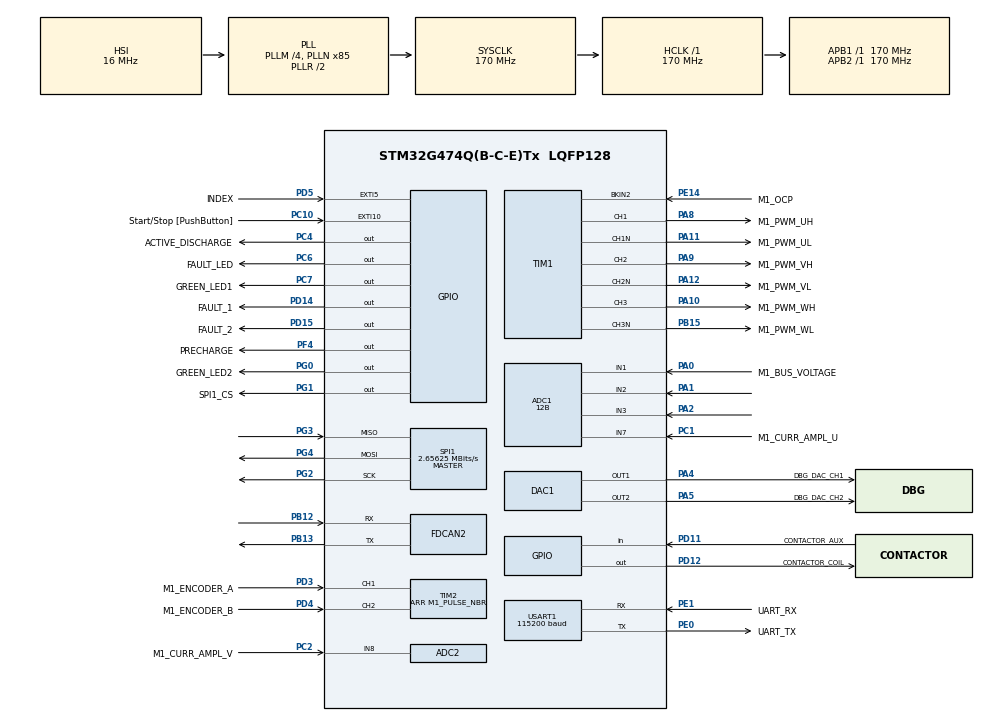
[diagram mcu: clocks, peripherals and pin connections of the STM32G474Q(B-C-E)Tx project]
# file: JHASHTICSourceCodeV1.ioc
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ADC1.Channel-1\#ChannelRegularConversion=ADC_CHANNEL_1
ADC1.Channel-2\#ChannelRegularConversion=ADC_CHANNEL_2
ADC1.Channel-3\#ChannelRegularConversion=ADC_CHANNEL_3
ADC1.ClockPrescaler=ADC_CLOCK_ASYNC_DIV4
ADC1.ContinuousConvMode=DISABLE
ADC1.DMAContinuousRequests=DISABLE
ADC1.DataAlign=ADC_DATAALIGN_LEFT
ADC1.DiscontinuousConvMode=DISABLE
ADC1.EOCSelection=ADC_EOC_SINGLE_CONV
ADC1.EnableAnalogWatchDog1=false
ADC1.EnableAnalogWatchDog2=false
ADC1.EnableAnalogWatchDog3=false
ADC1.EnableInjectedConversion=ENABLE
ADC1.EnableRegularConversion=ENABLE
ADC1.ExternalTrigConv=ADC_SOFTWARE_START
ADC1.ExternalTrigConvEdge=ADC_EXTERNALTRIGCONVEDGE_NONE
ADC1.ExternalTrigInjecConv=ADC_EXTERNALTRIGINJEC_T1_TRGO
ADC1.ExternalTrigInjecConvEdge=ADC_EXTERNALTRIGINJECCONV_EDGE_RISING
ADC1.InjNumberOfConversion=1
ADC1.InjectedChannel-1\#ChannelInjectedConversion=ADC_CHANNEL_7
ADC1.InjectedConvMode=None
ADC1.InjectedOffset-1\#ChannelInjectedConversion=0
ADC1.InjectedOffsetNumber-1\#ChannelInjectedConversion=ADC_OFFSET_NONE
ADC1.InjectedRank-1\#ChannelInjectedConversion=1
ADC1.InjectedSamplingTime-1\#ChannelInjectedConversion=ADC_SAMPLETIME_6CYCLES_5
ADC1.LowPowerAutoWait=DISABLE
ADC1.NbrOfConversion=3
ADC1.NbrOfConversionFlag=1
ADC1.Offset-1\#ChannelRegularConversion=0
ADC1.OffsetNumber-1\#ChannelRegularConversion=ADC_OFFSET_NONE
ADC1.OffsetNumber-2\#ChannelRegularConversion=ADC_OFFSET_NONE
ADC1.OffsetNumber-3\#ChannelRegularConversion=ADC_OFFSET_NONE
ADC1.Overrun=ADC_OVR_DATA_PRESERVED
ADC1.Rank-1\#ChannelRegularConversion=1
ADC1.Rank-2\#ChannelRegularConversion=2
ADC1.Rank-3\#ChannelRegularConversion=3
ADC1.Resolution=ADC_RESOLUTION_12B
ADC1.SamplingTime-1\#ChannelRegularConversion=ADC_SAMPLETIME_47CYCLES_5
ADC1.SamplingTime-2\#ChannelRegularConversion=ADC_SAMPLETIME_2CYCLES_5
ADC1.SamplingTime-3\#ChannelRegularConversion=ADC_SAMPLETIME_2CYCLES_5
ADC1.ScanConvMode=ADC_SCAN_ENABLE
ADC1.master=1
ADC2.ClockPrescaler=ADC_CLOCK_ASYNC_DIV4
ADC2.ContinuousConvMode=DISABLE
ADC2.DMAContinuousRequests=DISABLE
ADC2.DataAlign=ADC_DATAALIGN_LEFT
ADC2.DiscontinuousConvMode=DISABLE
ADC2.EOCSelection=ADC_EOC_SINGLE_CONV
ADC2.EnableAnalogWatchDog1=false
ADC2.EnableAnalogWatchDog2=false
ADC2.EnableAnalogWatchDog3=false
ADC2.EnableInjectedConversion=ENABLE
ADC2.EnableRegularConversion=DISABLE
ADC2.ExternalTrigInjecConv=ADC_EXTERNALTRIGINJEC_T1_TRGO
ADC2.ExternalTrigInjecConvEdge=ADC_EXTERNALTRIGINJECCONV_EDGE_RISING
ADC2.InjNumberOfConversion=1
ADC2.InjectedChannel-1\#ChannelInjectedConversion=ADC_CHANNEL_8
ADC2.InjectedConvMode=None
ADC2.InjectedOffset-1\#ChannelInjectedConversion=0
ADC2.InjectedOffsetNumber-1\#ChannelInjectedConversion=ADC_OFFSET_NONE
ADC2.InjectedRank-1\#ChannelInjectedConversion=1
ADC2.InjectedSamplingTime-1\#ChannelInjectedConversion=ADC_SAMPLETIME_6CYCLES_5
ADC2.LowPowerAutoWait=DISABLE
ADC2.Overrun=ADC_OVR_DATA_PRESERVED
ADC2.Resolution=ADC_RESOLUTION_12B
ADC2.ScanConvMode=ADC_SCAN_DISABLE
DAC1.DAC_Channel-DAC_OUT2=DAC_CHANNEL_2
DAC1.DAC_OutputBuffer=DAC_OUTPUTBUFFER_DISABLE
DAC1.DAC_OutputBuffer2=DAC_OUTPUTBUFFER_DISABLE
DAC1.DAC_Trigger_OUT1=DAC_TRIGGER_SOFTWARE
ExtraMW=MotorControl
ExtraMW.MotorControl.Config=MotorControl
ExtraMW.MotorControl.Mode=MotorControl
ExtraMW.MotorControl.Root=MCSDK_v5.4.7/MotorControl
ExtraMW.MotorControl.Template=templates
FDCAN2.AutoRetransmission=DISABLE
FDCAN2.DataPrescaler=1
FDCAN2.DataSyncJumpWidth=1
FDCAN2.DataTimeSeg1=1
FDCAN2.DataTimeSeg2=1
FDCAN2.FrameFormat=FDCAN_FRAME_CLASSIC
FDCAN2.NominalPrescaler=17
FDCAN2.NominalSyncJumpWidth=1
FDCAN2.NominalTimeSeg1=2
FDCAN2.NominalTimeSeg2=2
FDCAN2.TransmitPause=ENABLE
Mcu.Family=STM32G4
Mcu.Name=STM32G474Q(B-C-E)Tx
Mcu.Package=LQFP128
MotorControl.ADC_1_PERIPH=ADC1
MotorControl.ADC_2_PERIPH=ADC2
MotorControl.ADC_AHBPERIPH=RCC_AHBPeriph_ADC12
MotorControl.ADC_CLOCK_WB_DIV=4
MotorControl.ADC_CLOCK_WB_FREQ=42.5
MotorControl.ADC_PERIPH=ADC1
MotorControl.ADC_REFERENCE_VOLTAGE=3.30
MotorControl.ALIGNMENT_ANGLE_DEG=0
MotorControl.ALIGNMENT_DURATION=700
MotorControl.AMPLIFICATION_GAIN=0.009
MotorControl.ANGC={0,0,0,0,0,0,0,0}
MotorControl.BEMF_CONSISTENCY_GAIN=64
MotorControl.BEMF_CONSISTENCY_TOL=64
MotorControl.BKIN1_FILTER=0
MotorControl.BKIN2_FILTER=0
MotorControl.BKIN2_MODE=EXT_MODE
MotorControl.BKIN_MODE=NONE
MotorControl.BOARD=CUSTOM
MotorControl.BRKIN2_GPIO_AF=GPIO_AF_2
MotorControl.BRKIN_GPIO_AF=GPIO_AF_2
MotorControl.BUS_VOLTAGE_READING=true
MotorControl.CCMRAM_ENABLED=false
MotorControl.CLOCK_FREQUENCY=CPU_CLK_170_MHZ
MotorControl.CLOCK_SOURCE=INTERNAL
MotorControl.CONSTANT1_D=44442
MotorControl.CONSTANT1_Q=70509
MotorControl.CONSTANT2_QD=4316
MotorControl.CORD_BEMF_CONSISTENCY_GAIN=64
MotorControl.CORD_BEMF_CONSISTENCY_TOL=64
MotorControl.CORD_F1=16384
MotorControl.CORD_F2=8192
MotorControl.CORD_FIFO_DEPTH_01HZ=64
MotorControl.CORD_FIFO_DEPTH_DPP=64
MotorControl.CORD_GAIN1=-24465
MotorControl.CORD_GAIN2=30068
MotorControl.CORD_MAX_ACCEL_DPPP=193
MotorControl.CORD_MEAS_ERRORS_BEFORE_FAULTS=255
MotorControl.CORD_VARIANCE_THRESHOLD=4
MotorControl.CPU_CLK_170_MHZ=true
MotorControl.CTRBDID=0
MotorControl.CUBE_MX_VER=5.3.0
MotorControl.CURRENT_READING_TOPOLOGY=ICS_SENSORS
MotorControl.CURR_SAMPLING_TIME=6
MotorControl.DAC_EMULATED=false
MotorControl.DAC_FUNCTIONALITY=true
MotorControl.DAC_TIMER_CH1_GPIO_PIN=LL_GPIO_PIN_4
MotorControl.DAC_TIMER_CH1_GPIO_PORT=GPIOA
MotorControl.DAC_TIMER_CH2_GPIO_PIN=LL_GPIO_PIN_5
MotorControl.DAC_TIMER_CH2_GPIO_PORT=GPIOA
MotorControl.DAC_TIMER_SELECTION=TIM3
MotorControl.DC_CURRENT_RS_MEAS=30.00
MotorControl.DEBUG_DAC_CH1=true
MotorControl.DEBUG_DAC_CH2=true
MotorControl.DEFAULT_CONTROL_MODE=STC_SPEED_MODE
MotorControl.DEFAULT_DAC_CHANNEL_1=MC_PROTOCOL_REG_I_A
MotorControl.DEFAULT_DAC_CHANNEL_2=MC_PROTOCOL_REG_I_B
MotorControl.DEFAULT_DAC_MOTOR=0
MotorControl.DEFAULT_FLUX_COMPONENT=0
MotorControl.DEFAULT_TARGET_SPEED_RPM=0
MotorControl.DEFAULT_TORQUE_COMPONENT=0
MotorControl.DISSIPATIVE_BRAKE_POLARITY=DOUT_ACTIVE_HIGH
MotorControl.DRIVES_NUMBER_SELECTION=SINGLEDRIVE
MotorControl.EMERGENCY2_STOP_GPIO_PIN=LL_GPIO_PIN_14
MotorControl.EMERGENCY2_STOP_GPIO_PORT=GPIOE
MotorControl.EMERGENCY_STOP_GPIO_PIN=LL_GPIO_PIN_14
MotorControl.EMERGENCY_STOP_GPIO_PORT=GPIOE
MotorControl.ENABLE_SL_ALGO_FROM_PHASE=3
MotorControl.ENCODER=true
MotorControl.ENCODER_AVAILABLE=true
MotorControl.ENCODER_PPR=512
MotorControl.ENC_AVERAGING_FIFO_DEPTH=16
MotorControl.ENC_A_GPIO_PIN=LL_GPIO_PIN_3
MotorControl.ENC_A_GPIO_PORT=GPIOD
MotorControl.ENC_B_GPIO_PIN=LL_GPIO_PIN_4
MotorControl.ENC_B_GPIO_PORT=GPIOD
MotorControl.ENC_ICx_FILTER=128
MotorControl.ENC_INVERT_SPEED=false
MotorControl.ENC_MEAS_ERRORS_BEFORE_FAULTS=255
MotorControl.ENC_TIMER_REMAPPING=NO_REMAP_TIM2
MotorControl.ENC_TIMER_SELECTION=ENC_TIM2
MotorControl.ENC_USE_CH3=false
MotorControl.EXT_CLOCK_FREQUENCY=INT_RC_OSC
MotorControl.F1=16384
MotorControl.F2=8192
MotorControl.FEEDBACK_NET_FILTERING=false
MotorControl.FEED_FORWARD_CURRENT_REG_ENABLING=false
MotorControl.FINAL_I_ALIGNMENT=348
MotorControl.FLUX_WEAKENING_ENABLING=false
MotorControl.FW_KIDIV=32768
MotorControl.FW_KI_GAIN=5000
MotorControl.FW_KPDIV=32768
MotorControl.FW_KP_GAIN=3000
MotorControl.FW_VOLTAGE_REF=985
MotorControl.GAIN1=-24465
MotorControl.GAIN2=30068
MotorControl.H1_GPIO_PIN=LL_GPIO_PIN_0
MotorControl.H1_GPIO_PORT=GPIOA
MotorControl.H2_GPIO_PIN=LL_GPIO_PIN_3
MotorControl.H2_GPIO_PORT=GPIOB
MotorControl.H3_GPIO_PIN=LL_GPIO_PIN_10
MotorControl.H3_GPIO_PORT=GPIOB
MotorControl.HALL_AVERAGING_FIFO_DEPTH=6
MotorControl.HALL_ICx_FILTER=221
MotorControl.HALL_MEAS_ERRORS_BEFORE_FAULTS=255
MotorControl.HALL_MTPA=false
MotorControl.HALL_PHASE_SHIFT=300
MotorControl.HALL_SENSORS_AVAILABLE=false
MotorControl.HALL_SENSORS_PLACEMENT=DEGREES_120
MotorControl.HALL_TIMER_REMAPPING=NO_REMAP_TIM2
MotorControl.HALL_TIMER_SELECTION=HALL_TIM2
MotorControl.HFI_AMPLITUDE=25
MotorControl.HFI_DC_0_COEFF=0.00146
MotorControl.HFI_DC_1_COEFF=0.002921
MotorControl.HFI_DC_2_COEFF=0.00146
MotorControl.HFI_DC_3_COEFF=1.889033
MotorControl.HFI_DC_4_COEFF=-0.894874
MotorControl.HFI_DEBUG_MODE=false
MotorControl.HFI_FREQUENCY=400
MotorControl.HFI_HIFRAMPLSCAN=25
MotorControl.HFI_HP_ID_0_COEFF=0.883002
MotorControl.HFI_HP_ID_1_COEFF=-1.766004
MotorControl.HFI_HP_ID_2_COEFF=0.883002
MotorControl.HFI_HP_ID_3_COEFF=1.752268
MotorControl.HFI_HP_ID_4_COEFF=-0.779739
MotorControl.HFI_IDH_DELAY=32400
MotorControl.HFI_LOCKFREQ=66
MotorControl.HFI_LP_ID_0_COEFF=0.021558
MotorControl.HFI_LP_ID_1_COEFF=0.043117
MotorControl.HFI_LP_ID_2_COEFF=0.021558
MotorControl.HFI_LP_ID_3_COEFF=1.543836
MotorControl.HFI_LP_ID_4_COEFF=-0.63007
MotorControl.HFI_MAXANGLEDIFF=3640
MotorControl.HFI_MINIMUM_SPEED_RPM=402
MotorControl.HFI_NOTCH_IQD_0_COEFF=0.941467
MotorControl.HFI_NOTCH_IQD_1_COEFF=-1.823778
MotorControl.HFI_NOTCH_IQD_2_COEFF=0.941467
MotorControl.HFI_NOTCH_IQD_3_COEFF=1.823778
MotorControl.HFI_NOTCH_IQD_4_COEFF=-0.882933
MotorControl.HFI_NSDETPOINTSSKIP=10
MotorControl.HFI_NSMAXDETPOINTS=20
MotorControl.HFI_NS_MIN_SAT_DIFF=0
MotorControl.HFI_PID_KIDIV=32768
MotorControl.HFI_PID_KI_DEFAULT=400
MotorControl.HFI_PID_KPDIV=16384
MotorControl.HFI_PID_KP_DEFAULT=800
MotorControl.HFI_PLL_KI_DEFAULT=0.00400
MotorControl.HFI_PLL_KP_DEFAULT=0.00060
MotorControl.HFI_RESTARTTIMESEC=0.1
MotorControl.HFI_RESTART_RPM_TH=(((HFI_STO_RPM_TH)+(STO_HFI_RPM_TH))/2)
MotorControl.HFI_REVERT_DIRECTION=true
MotorControl.HFI_SCANROTATIONSNO=3
MotorControl.HFI_SPD_BUFFER_DEPTH_01HZ=64
MotorControl.HFI_STEPANGLE=3640
MotorControl.HFI_STO_RPM_TH=OBS_MINIMUM_SPEED_RPM
MotorControl.HFI_WAITAFTERNS2=4
MotorControl.HFI_WAITBEFORESN=6
MotorControl.HFI_WAITSYNCH=20
MotorControl.HFI_WAITTRACK=20
MotorControl.HIGH_SIDE_BRAKE_STATE=false
MotorControl.HIGH_SIDE_IDLE_STATE=false
MotorControl.HW_COMPLEMENTED_LOW_SIDE=false
MotorControl.HW_DEAD_TIME_NS=100
MotorControl.HW_OV_CURRENT_PROT_BYPASS=false
MotorControl.ICS_SENSORS=true
MotorControl.ID_DEMAG=-5361
MotorControl.INRUSH_CURRLIMIT_AT_POWER_ON=true
MotorControl.INRUSH_CURRLIMIT_CHANGE_AFTER_MS=1000
MotorControl.INRUSH_CURRLIMIT_ENABLING=false
MotorControl.INRUSH_CURRLIMIT_GPIO_PIN=LL_GPIO_PIN_4
MotorControl.INRUSH_CURRLIMIT_GPIO_PORT=GPIOE
MotorControl.INRUSH_CURR_LIMITER_POLARITY=DOUT_ACTIVE_HIGH
MotorControl.INTERNAL_OVERCURRENTPROTECTION=false
MotorControl.INTERNAL_OVERVOLTAGEPROTECTION=false
MotorControl.INT_RC_OSC=true
MotorControl.IPs=CORDIC,NVIC,RCC,SYS,MotorControl,TIM1,ADC1,ADC2,TIM2,DAC1,USART1
MotorControl.IQMAX=5361
MotorControl.LCD_JOYSTICK_FUNCTIONALITY=false
MotorControl.LCD_MODE=LCD_FULL
MotorControl.LDLQ_RATIO=0.630
MotorControl.LOW_SIDE_BRAKE_STATE=false
MotorControl.LOW_SIDE_IDLE_STATE=false
MotorControl.LOW_SIDE_SIGNALS_ENABLING=LS_PWM_TIMER
MotorControl.LS=0.000330
MotorControl.MAX_APPLICATION_SPEED=5000
MotorControl.MAX_MODULATION_100_PER_CENT=true
MotorControl.MAX_MODULATION_INDEX=MAX_MODULATION_100_PER_CENT
MotorControl.MCU=STM32G474QE
MotorControl.MCU_TYPE=STM32G474QE
MotorControl.MC_WORKBENCH_VERSION=5.4.7.21279
MotorControl.MEAS_ERRORS_BEFORE_FAULTS=255
MotorControl.MIN_APPLICATION_SPEED=0
MotorControl.MOTOR_MAX_SPEED_RPM=5000
MotorControl.MOTOR_TYPE=PMSM
MotorControl.MOTOR_VOLTAGE_CONSTANT=19.0
MotorControl.MTPA_ENABLING=false
MotorControl.NB_CONSECUTIVE_TESTS=2
MotorControl.NOMINAL_BUS_VOLTAGE_V=60
MotorControl.NOMINAL_CURRENT=5361
MotorControl.OBS_MEAS_ERRORS_BEFORE_FAULTS=255
MotorControl.OBS_MINIMUM_SPEED_RPM=580
MotorControl.OCPA_INVERTINGINPUT=COMPX_InvertingInput_VREF
MotorControl.OCPA_INVERTINGINPUT_GPIO_PIN=LL_GPIO_PIN_4
MotorControl.OCPA_INVERTINGINPUT_GPIO_PORT=GPIOA
MotorControl.OCPA_INVERTINGINPUT_MODE=INT_MODE
MotorControl.OCPA_NONINVERTINGINPUT=COMP1_NonInvertingInput_PA1
MotorControl.OCPA_NONINVERTINGINPUT_GPIO_PIN=LL_GPIO_PIN_1
MotorControl.OCPA_NONINVERTINGINPUT_GPIO_PORT=GPIOA
MotorControl.OCPA_OUTPUT=COMP_Output_TIM1BKIN2
MotorControl.OCPA_OUTPUTPOL=COMP_OutputPol_NonInverted
MotorControl.OCPA_OUTPUT_GPIO_AF=GPIO_AF_2
MotorControl.OCPA_OUTPUT_GPIO_PIN=LL_GPIO_PIN_0
MotorControl.OCPA_OUTPUT_GPIO_PORT=GPIOA
MotorControl.OCPA_OUTPUT_MODE=INT_MODE
MotorControl.OCPA_SELECTION=COMP1
MotorControl.OCPB_INVERTINGINPUT=COMPX_InvertingInput_VREF
MotorControl.OCPB_INVERTINGINPUT_GPIO_PIN=LL_GPIO_PIN_4
MotorControl.OCPB_INVERTINGINPUT_GPIO_PORT=GPIOA
MotorControl.OCPB_INVERTINGINPUT_MODE=INT_MODE
MotorControl.OCPB_NONINVERTINGINPUT=COMP2_NonInvertingInput_PA7
MotorControl.OCPB_NONINVERTINGINPUT_GPIO_PIN=LL_GPIO_PIN_7
MotorControl.OCPB_NONINVERTINGINPUT_GPIO_PORT=GPIOA
MotorControl.OCPB_OUTPUT=COMP_Output_TIM1BKIN2
MotorControl.OCPB_OUTPUTPOL=COMP_OutputPol_NonInverted
MotorControl.OCPB_OUTPUT_GPIO_AF=GPIO_AF_2
MotorControl.OCPB_OUTPUT_GPIO_PIN=LL_GPIO_PIN_2
MotorControl.OCPB_OUTPUT_GPIO_PORT=GPIOA
MotorControl.OCPB_OUTPUT_MODE=INT_MODE
MotorControl.OCPB_SELECTION=COMP2
MotorControl.OCPC_INVERTINGINPUT=COMPX_InvertingInput_VREF
MotorControl.OCPC_INVERTINGINPUT_GPIO_PIN=LL_GPIO_PIN_4
MotorControl.OCPC_INVERTINGINPUT_GPIO_PORT=GPIOA
MotorControl.OCPC_INVERTINGINPUT_MODE=INT_MODE
MotorControl.OCPC_NONINVERTINGINPUT=COMP3_NonInvertingInput_PD14
MotorControl.OCPC_NONINVERTINGINPUT_GPIO_PIN=LL_GPIO_PIN_14
MotorControl.OCPC_NONINVERTINGINPUT_GPIO_PORT=GPIOD
MotorControl.OCPC_OUTPUT=COMP_Output_TIM1BKIN2
MotorControl.OCPC_OUTPUTPOL=COMP_OutputPol_NonInverted
MotorControl.OCPC_OUTPUT_GPIO_AF=GPIO_AF_2
MotorControl.OCPC_OUTPUT_GPIO_PIN=LL_GPIO_PIN_8
MotorControl.OCPC_OUTPUT_GPIO_PORT=GPIOC
MotorControl.OCPC_OUTPUT_MODE=INT_MODE
MotorControl.OCPC_SELECTION=COMP3
MotorControl.OCPREF=23830
MotorControl.OCP_COMP_THRESHOLD=1.65
MotorControl.OCP_FILTER=COMP_Mode_HighSpeed
MotorControl.OCP_INVERTINGINPUT=COMPX_InvertingInput_VREF
MotorControl.OCP_INVERTINGINPUT_GPIO_PIN=LL_GPIO_PIN_4
MotorControl.OCP_INVERTINGINPUT_GPIO_PORT=GPIOA
MotorControl.OCP_INVERTINGINPUT_MODE=INT_MODE
MotorControl.OCP_NONINVERTINGINPUT=COMP2_NonInvertingInput_PA7
MotorControl.OCP_NONINVERTINGINPUT_GPIO_PIN=LL_GPIO_PIN_7
MotorControl.OCP_NONINVERTINGINPUT_GPIO_PORT=GPIOA
MotorControl.OCP_OUTPUT=COMP_Output_TIM1BKIN2
MotorControl.OCP_OUTPUTPOL=COMP_OutputPol_NonInverted
MotorControl.OCP_OUTPUT_GPIO_AF=GPIO_AF_2
MotorControl.OCP_OUTPUT_GPIO_PIN=LL_GPIO_PIN_2
MotorControl.OCP_OUTPUT_GPIO_PORT=GPIOA
MotorControl.OCP_OUTPUT_MODE=INT_MODE
MotorControl.OCP_SELECTION=COMP2
MotorControl.OFST={0,0,0,0,0,0,0,0}
MotorControl.ON_OVER_VOLTAGE=TURN_OFF_PWM
MotorControl.OPAMP1_INVERTINGINPUT=OPAMP1_InvertingInput_PGA
MotorControl.OPAMP1_INVERTINGINPUT_GPIO_PIN=LL_GPIO_PIN_3
MotorControl.OPAMP1_INVERTINGINPUT_GPIO_PORT=GPIOA
MotorControl.OPAMP1_INVERTINGINPUT_MODE=INT_MODE
MotorControl.OPAMP1_NONINVERTINGINPUT_PHA=OPAMP1_NonInvertingInput_PA1
MotorControl.OPAMP1_NONINVERTINGINPUT_PHA_GPIO_PIN=LL_GPIO_PIN_1
MotorControl.OPAMP1_NONINVERTINGINPUT_PHA_GPIO_PORT=GPIOA
MotorControl.OPAMP1_NONINVERTINGINPUT_PHB=OPAMP1_NonInvertingInput_PA7
MotorControl.OPAMP1_NONINVERTINGINPUT_PHB_GPIO_PIN=LL_GPIO_PIN_7
MotorControl.OPAMP1_NONINVERTINGINPUT_PHB_GPIO_PORT=GPIOA
MotorControl.OPAMP1_OUT_GPIO_PIN=LL_GPIO_PIN_2
MotorControl.OPAMP1_OUT_GPIO_PORT=GPIOA
MotorControl.OPAMP1_SELECTION=OPAMP1
MotorControl.OPAMP2_INVERTINGINPUT=OPAMP2_InvertingInput_PGA
MotorControl.OPAMP2_INVERTINGINPUT_GPIO_PIN=LL_GPIO_PIN_5
MotorControl.OPAMP2_INVERTINGINPUT_GPIO_PORT=GPIOC
MotorControl.OPAMP2_INVERTINGINPUT_MODE=INT_MODE
MotorControl.OPAMP2_NONINVERTINGINPUT_PHA=OPAMP2_NonInvertingInput_PB14
MotorControl.OPAMP2_NONINVERTINGINPUT_PHA_GPIO_PIN=LL_GPIO_PIN_14
MotorControl.OPAMP2_NONINVERTINGINPUT_PHA_GPIO_PORT=GPIOB
MotorControl.OPAMP2_NONINVERTINGINPUT_PHB=OPAMP2_NonInvertingInput_PA7
MotorControl.OPAMP2_NONINVERTINGINPUT_PHB_GPIO_PIN=LL_GPIO_PIN_7
MotorControl.OPAMP2_NONINVERTINGINPUT_PHB_GPIO_PORT=GPIOA
MotorControl.OPAMP2_NONINVERTINGINPUT_PHC=OPAMP2_NonInvertingInput_PB14
MotorControl.OPAMP2_NONINVERTINGINPUT_PHC_GPIO_PIN=LL_GPIO_PIN_14
MotorControl.OPAMP2_NONINVERTINGINPUT_PHC_GPIO_PORT=GPIOB
MotorControl.OPAMP2_OUT_GPIO_PIN=LL_GPIO_PIN_6
MotorControl.OPAMP2_OUT_GPIO_PORT=GPIOA
MotorControl.OPAMP2_SELECTION=OPAMP2
MotorControl.OPAMP3_INVERTINGINPUT=OPAMP1_InvertingInput_PGA
MotorControl.OPAMP3_INVERTINGINPUT_GPIO_PIN=LL_GPIO_PIN_0
MotorControl.OPAMP3_INVERTINGINPUT_GPIO_PORT=GPIOA
MotorControl.OPAMP3_INVERTINGINPUT_MODE=INT_MODE
MotorControl.OPAMP3_SELECTION=OPAMP1
MotorControl.OPAMP_INVERTINGINPUT=OPAMP1_InvertingInput_PGA
MotorControl.OPAMP_INVERTINGINPUT_GPIO_PIN=LL_GPIO_PIN_3
MotorControl.OPAMP_INVERTINGINPUT_GPIO_PORT=GPIOA
MotorControl.OPAMP_INVERTINGINPUT_MODE=INT_MODE
MotorControl.OPAMP_NONINVERTINGINPUT=OPAMP1_NonInvertingInput_PA7
MotorControl.OPAMP_NONINVERTINGINPUT_GPIO_PIN=LL_GPIO_PIN_7
MotorControl.OPAMP_NONINVERTINGINPUT_GPIO_PORT=GPIOA
MotorControl.OPAMP_OUT_GPIO_PIN=LL_GPIO_PIN_2
MotorControl.OPAMP_OUT_GPIO_PORT=GPIOA
MotorControl.OPAMP_PGACONNECT=OPAMP_PGAConnect_No
MotorControl.OPAMP_PGAGAIN=OPAMP_OPAMP_PGAGain_2
MotorControl.OPAMP_SELECTION=OPAMP1
MotorControl.OPAMP_TYPE_GAIN=INTERNAL
MotorControl.OPEN_LOOP_FOC=false
MotorControl.OPEN_LOOP_K=44
MotorControl.OPEN_LOOP_OFF=4400
MotorControl.OPEN_LOOP_SPEED_RAMP_DURATION_MS=1000
MotorControl.OPEN_LOOP_SPEED_RPM=100
MotorControl.OPEN_LOOP_VF=false
MotorControl.OPEN_LOOP_VOLTAGE_d=6000
MotorControl.OVERCURR_FEEDBACK_POLARITY=EMSTOP_ACTIVE_LOW
MotorControl.OVERCURR_PROTECTION_HW_DISABLING=DOUT_ACTIVE_HIGH
MotorControl.OVPREF=23830
MotorControl.OVP_FILTER=COMP_Mode_HighSpeed
MotorControl.OVP_INVERTINGINPUT=COMPX_InvertingInput_VREF
MotorControl.OVP_INVERTINGINPUT_GPIO_PIN=LL_GPIO_PIN_4
MotorControl.OVP_INVERTINGINPUT_GPIO_PORT=GPIOA
MotorControl.OVP_INVERTINGINPUT_MODE=INT_MODE
MotorControl.OVP_NONINVERTINGINPUT=COMP7_NonInvertingInput_PA0
MotorControl.OVP_NONINVERTINGINPUT_GPIO_PIN=LL_GPIO_PIN_0
MotorControl.OVP_NONINVERTINGINPUT_GPIO_PORT=GPIOA
MotorControl.OVP_OUTPUT=COMP_Output_TIM1BKIN
MotorControl.OVP_OUTPUTPOL=COMP_OutputPol_NonInverted
MotorControl.OVP_OUTPUT_GPIO_AF=GPIO_AF_2
MotorControl.OVP_OUTPUT_GPIO_PIN=LL_GPIO_PIN_2
MotorControl.OVP_OUTPUT_GPIO_PORT=GPIOC
MotorControl.OVP_OUTPUT_MODE=INT_MODE
MotorControl.OVP_SELECTION=COMP7
MotorControl.OV_CURR_BYPASS_GPIO_PIN=LL_GPIO_PIN_5
MotorControl.OV_CURR_BYPASS_GPIO_PORT=GPIOE
MotorControl.OV_TEMPERATURE_HYSTERESIS_C=10
MotorControl.OV_TEMPERATURE_PROT_ENABLING=false
MotorControl.OV_TEMPERATURE_THRESHOLD_C=70
MotorControl.OV_VOLTAGE_PROT_ENABLING=true
MotorControl.OV_VOLTAGE_THRESHOLD_V=420
MotorControl.PHASE1_DURATION=0
MotorControl.PHASE1_FINAL_CURRENT=0
MotorControl.PHASE1_FINAL_SPEED_RPM=0
MotorControl.PHASE2_DURATION=700
MotorControl.PHASE2_FINAL_CURRENT=107
MotorControl.PHASE2_FINAL_SPEED_RPM=0
MotorControl.PHASE3_DURATION=350
MotorControl.PHASE3_FINAL_CURRENT=125
MotorControl.PHASE3_FINAL_SPEED_RPM=630
MotorControl.PHASE4_DURATION=1150
MotorControl.PHASE4_FINAL_CURRENT=125
MotorControl.PHASE4_FINAL_SPEED_RPM=2700
MotorControl.PHASE5_DURATION=0
MotorControl.PHASE5_FINAL_CURRENT=125
MotorControl.PHASE5_FINAL_SPEED_RPM=2700
MotorControl.PHASE_CURRENTS_ADC=ADC1_2
MotorControl.PHASE_CURRENTS_CHANNEL=ADC_CHANNEL_9
MotorControl.PHASE_CURRENTS_GPIO_PIN=LL_GPIO_PIN_3
MotorControl.PHASE_CURRENTS_GPIO_PORT=GPIOC
MotorControl.PHASE_UH_GPIO_AF=GPIO_AF_6
MotorControl.PHASE_UH_GPIO_PIN=LL_GPIO_PIN_8
MotorControl.PHASE_UH_GPIO_PORT=GPIOA
MotorControl.PHASE_UH_POLARITY=H_ACTIVE_HIGH
MotorControl.PHASE_UL_GPIO_AF=GPIO_AF_6
MotorControl.PHASE_UL_GPIO_PIN=LL_GPIO_PIN_11
MotorControl.PHASE_UL_GPIO_PORT=GPIOA
MotorControl.PHASE_UL_POLARITY=L_ACTIVE_HIGH
MotorControl.PHASE_U_CURR_ADC=ADC1_2
MotorControl.PHASE_U_CURR_CHANNEL=ADC_CHANNEL_7
MotorControl.PHASE_U_GPIO_PIN=LL_GPIO_PIN_1
MotorControl.PHASE_U_GPIO_PORT=GPIOC
MotorControl.PHASE_VH_GPIO_AF=GPIO_AF_6
MotorControl.PHASE_VH_GPIO_PIN=LL_GPIO_PIN_9
MotorControl.PHASE_VH_GPIO_PORT=GPIOA
MotorControl.PHASE_VH_POLARITY=H_ACTIVE_HIGH
MotorControl.PHASE_VL_GPIO_AF=GPIO_AF_2
MotorControl.PHASE_VL_GPIO_PIN=LL_GPIO_PIN_12
MotorControl.PHASE_VL_GPIO_PORT=GPIOA
MotorControl.PHASE_VL_POLARITY=L_ACTIVE_HIGH
MotorControl.PHASE_V_CURR_ADC=ADC1_2
MotorControl.PHASE_V_CURR_CHANNEL=ADC_CHANNEL_8
MotorControl.PHASE_V_GPIO_PIN=LL_GPIO_PIN_2
MotorControl.PHASE_V_GPIO_PORT=GPIOC
MotorControl.PHASE_WH_GPIO_AF=GPIO_AF_6
MotorControl.PHASE_WH_GPIO_PIN=LL_GPIO_PIN_10
MotorControl.PHASE_WH_GPIO_PORT=GPIOA
MotorControl.PHASE_WH_POLARITY=H_ACTIVE_HIGH
MotorControl.PHASE_WL_GPIO_AF=GPIO_AF_4
MotorControl.PHASE_WL_GPIO_PIN=LL_GPIO_PIN_15
MotorControl.PHASE_WL_GPIO_PORT=GPIOB
MotorControl.PHASE_WL_POLARITY=L_ACTIVE_HIGH
MotorControl.PHASE_W_CURR_ADC=ADC1_2
MotorControl.PHASE_W_CURR_CHANNEL=ADC_CHANNEL_6
MotorControl.PHASE_W_GPIO_PIN=LL_GPIO_PIN_0
MotorControl.PHASE_W_GPIO_PORT=GPIOC
MotorControl.PID_FLUX_KD_DEFAULT=100
MotorControl.PID_FLUX_KI_DEFAULT=30
MotorControl.PID_FLUX_KP_DEFAULT=2083
MotorControl.PID_SPEED_KD_DEFAULT=0
MotorControl.PID_SPEED_KI_DEFAULT=25
MotorControl.PID_SPEED_KP_DEFAULT=5000
MotorControl.PID_TORQUE_KD_DEFAULT=100
MotorControl.PID_TORQUE_KI_DEFAULT=30
MotorControl.PID_TORQUE_KP_DEFAULT=3304
MotorControl.PLL_KI_GAIN=94
MotorControl.PLL_KP_GAIN=1330
MotorControl.POLE_PAIR_NUM=5
MotorControl.POSITION_CTRL_ENABLING=false
MotorControl.PWBDID=0
MotorControl.PWM_FREQUENCY=10000
MotorControl.PWM_TIMER_REMAPPING=PWM_NO_REMAP
MotorControl.PWM_TIMER_SELECTION=PWM_TIM1
MotorControl.REGCONVADC=ADC1
MotorControl.REGULATION_EXECUTION_RATE=1
MotorControl.RS=0.03
MotorControl.RSHUNT=0.22000
MotorControl.RTOS=NONE
MotorControl.R_BRAKE_GPIO_PIN=LL_GPIO_PIN_5
MotorControl.R_BRAKE_GPIO_PORT=GPIOE
MotorControl.R_BRAKE_SWITCH_OFF_THRES_V=336
MotorControl.SEGDIV=0
MotorControl.SERIAL_COMMUNICATION=true
MotorControl.SERIAL_COM_CHANNEL1=MC_PROTOCOL_REG_I_A
MotorControl.SERIAL_COM_CHANNEL2=MC_PROTOCOL_REG_I_A
MotorControl.SERIAL_COM_MODE=COM_BIDIRECTIONAL
MotorControl.SERIAL_COM_MOTOR=0
MotorControl.SHARED_SIGNAL_ENABLE=false
MotorControl.SINGLEDRIVE=true
MotorControl.SPD_DIFFERENTIAL_TERM_ENABLING=false
MotorControl.SPEED_BAND_LOWER_LIMIT=15
MotorControl.SPEED_BAND_UPPER_LIMIT=17
MotorControl.SPEED_LOOP_FREQUENCY_HZ=1000
MotorControl.SPEED_SENSOR_SELECTION=ENCODER
MotorControl.SP_KDDIV=16
MotorControl.SP_KIDIV=1024
MotorControl.SP_KPDIV=256
MotorControl.STARTING_ANGLE_DEG=90
MotorControl.START_STOP_BTN=true
MotorControl.START_STOP_GPIO_PIN=LL_GPIO_PIN_10
MotorControl.START_STOP_GPIO_PORT=GPIOC
MotorControl.START_STOP_POLARITY=DIN_ACTIVE_LOW
MotorControl.START_STOP_POLARITY_EDGE=GPIO_NOPULL
MotorControl.STM32G474QE=true
MotorControl.STO_FIFO_DEPTH_01HZ=64
MotorControl.STO_FIFO_DEPTH_DPP=64
MotorControl.STO_HFI_RPM_TH=460
MotorControl.SW_DEADTIME_NS=3000
MotorControl.SW_OV_CURRENT_PROT_ENABLING=true
MotorControl.T0_C=25
MotorControl.TEMPERATURE_READING=false
MotorControl.TEMP_ADC_SAMPLING_TIME=47
MotorControl.TEMP_FDBK_ADC=ADC1
MotorControl.TEMP_FDBK_CHANNEL=ADC_CHANNEL_5
MotorControl.TEMP_FDBK_GPIO_PIN=LL_GPIO_PIN_14
MotorControl.TEMP_FDBK_GPIO_PORT=GPIOB
MotorControl.TFDIFFERENTIAL_TERM_ENABLING=false
MotorControl.TF_KDDIV=8192
MotorControl.TF_KIDIV=16384
MotorControl.TF_KPDIV=16384
MotorControl.TNOISE_NS=2550
MotorControl.TRANSITION_DURATION=25
MotorControl.TRISE_NS=2550
MotorControl.T_MAX=70
MotorControl.UD_VOLTAGE_THRESHOLD_V=50
MotorControl.USART_REMAPPING=NO_REMAP_USART1
MotorControl.USART_RX_GPIO_PIN=LL_GPIO_PIN_1
MotorControl.USART_RX_GPIO_PORT=GPIOE
MotorControl.USART_SELECTION=USE_USART1
MotorControl.USART_SPEED=115200
MotorControl.USART_TX_GPIO_PIN=LL_GPIO_PIN_0
MotorControl.USART_TX_GPIO_PORT=GPIOE
MotorControl.USE_3OPAMPS=false
MotorControl.USE_INTERNAL_OPAMP=false
MotorControl.UV_VOLTAGE_PROT_ENABLING=true
MotorControl.V0_V=0.290
MotorControl.VARIANCE_THRESHOLD=0.1
MotorControl.VBUS_ADC=ADC1
MotorControl.VBUS_ADC_SAMPLING_TIME=47
MotorControl.VBUS_CHANNEL=ADC_CHANNEL_1
MotorControl.VBUS_GPIO_PIN=LL_GPIO_PIN_0
MotorControl.VBUS_GPIO_PORT=GPIOA
MotorControl.VBUS_PARTITIONING_FACTOR=0.0037
MotorControl.WB_to_Mx_template_version=21-02-18
MotorControl.WB_to_Mx_version=1.4.0
MotorControl.dV_dT=0.025
NVIC.ADC1_2_IRQn=true\:2\:0\:true\:true\:false\:3\:true\:true
NVIC.EXTI15_10_IRQn=true\:3\:0\:false\:true\:false\:6\:true\:true
NVIC.EXTI9_5_IRQn=true\:0\:0\:false\:false\:true\:true\:true
NVIC.FDCAN2_IT0_IRQn=true\:0\:0\:false\:false\:true\:true\:true
NVIC.FDCAN2_IT1_IRQn=true\:0\:0\:false\:false\:true\:true\:true
NVIC.PriorityGroup=NVIC_PRIORITYGROUP_3
NVIC.TIM1_BRK_TIM15_IRQn=true\:4\:1\:true\:true\:false\:1\:true\:true
NVIC.TIM1_TRG_COM_TIM17_IRQn=true\:0\:0\:false\:false\:true\:true\:true
NVIC.TIM1_UP_TIM16_IRQn=true\:0\:0\:false\:true\:false\:2\:true\:true
NVIC.TIM2_IRQn=true\:3\:0\:false\:true\:false\:4\:true\:true
NVIC.TIM7_DAC_IRQn=true\:0\:0\:false\:false\:true\:true\:true
NVIC.USART1_IRQn=true\:3\:1\:true\:true\:false\:5\:true\:true
PA0.GPIO_Label=M1_BUS_VOLTAGE
PA0.Mode=IN1-Single-Ended
PA0.Signal=ADC1_IN1
PA1.Mode=IN2-Single-Ended
PA1.Signal=ADC1_IN2
PA10.GPIO_Label=M1_PWM_WH
PA10.GPIO_PuPd=GPIO_PULLDOWN
PA10.GPIO_Speed=GPIO_SPEED_FREQ_HIGH
PA10.Signal=S_TIM1_CH3
PA11.GPIO_Label=M1_PWM_UL
PA11.GPIO_PuPd=GPIO_PULLDOWN
PA11.GPIO_Speed=GPIO_SPEED_FREQ_HIGH
PA11.Mode=PWM Generation1 CH1 CH1N
PA11.Signal=TIM1_CH1N
PA12.GPIO_Label=M1_PWM_VL
PA12.GPIO_PuPd=GPIO_PULLDOWN
PA12.GPIO_Speed=GPIO_SPEED_FREQ_HIGH
PA12.Mode=PWM Generation2 CH2 CH2N
PA12.Signal=TIM1_CH2N
PA13.GPIO_Label=TMS
PA13.Mode=Serial_Wire
PA13.Signal=SYS_JTMS-SWDIO
PA14.GPIO_Label=TCK
PA14.Mode=Serial_Wire
PA14.Signal=SYS_JTCK-SWCLK
PA2.Mode=IN3-Single-Ended
PA2.Signal=ADC1_IN3
PA4.GPIO_Label=DBG_DAC_CH1
PA4.Signal=COMP_DAC11_group
PA5.GPIO_Label=DBG_DAC_CH2
PA5.Signal=COMP_DAC12_group
PA8.GPIO_Label=M1_PWM_UH
PA8.GPIO_PuPd=GPIO_PULLDOWN
PA8.GPIO_Speed=GPIO_SPEED_FREQ_HIGH
PA8.Signal=S_TIM1_CH1
PA9.GPIO_Label=M1_PWM_VH
PA9.GPIO_PuPd=GPIO_PULLDOWN
PA9.GPIO_Speed=GPIO_SPEED_FREQ_HIGH
PA9.Signal=S_TIM1_CH2
PB12.Mode=FDCANSlave
PB12.Signal=FDCAN2_RX
PB13.Mode=FDCANSlave
PB13.Signal=FDCAN2_TX
PB15.GPIO_Label=M1_PWM_WL
PB15.GPIO_PuPd=GPIO_PULLDOWN
PB15.GPIO_Speed=GPIO_SPEED_FREQ_HIGH
PB15.Mode=PWM Generation3 CH3 CH3N
PB15.Signal=TIM1_CH3N
PC1.GPIO_Label=M1_CURR_AMPL_U
PC1.Mode=IN7-Single-Ended
PC1.Signal=ADC1_IN7
PC10.GPIO_Label=Start/Stop [PushButton]
PC10.GPIO_ModeDefaultEXTI=GPIO_MODE_IT_FALLING
PC10.GPIO_PuPd=GPIO_NOPULL
PC10.Signal=GPXTI10
PC2.GPIO_Label=M1_CURR_AMPL_V
PC2.Mode=IN8-Single-Ended
PC2.Signal=ADC2_IN8
PC4.GPIO_Label=ACTIVE_DISCHARGE
PC4.Signal=GPIO_Output
PC6.GPIO_Label=FAULT_LED
PC6.Signal=GPIO_Output
PC7.GPIO_Label=GREEN_LED1
PC7.Signal=GPIO_Output
PD11.GPIO_Label=CONTACTOR_AUX
PD11.Signal=GPIO_Input
PD12.GPIO_Label=CONTACTOR_COIL
PD12.PinState=GPIO_PIN_SET
PD12.Signal=GPIO_Output
PD14.GPIO_Label=FAULT_1
PD14.Signal=GPIO_Output
PD15.GPIO_Label=FAULT_2
PD15.Signal=GPIO_Output
PD3.GPIO_Label=M1_ENCODER_A
PD3.Signal=S_TIM2_CH1
PD4.GPIO_Label=M1_ENCODER_B
PD4.Signal=S_TIM2_CH2
PD5.GPIO_Label=INDEX
PD5.Signal=GPXTI5
PE0.GPIO_Label=UART_TX
PE0.GPIO_Mode=GPIO_MODE_AF_PP
PE0.GPIO_PuPd=GPIO_NOPULL
PE0.GPIO_Speed=GPIO_SPEED_FREQ_LOW
PE0.Mode=Asynchronous
PE0.Signal=USART1_TX
PE1.GPIO_Label=UART_RX
PE1.GPIO_Mode=GPIO_MODE_AF_PP
PE1.GPIO_PuPd=GPIO_NOPULL
PE1.GPIO_Speed=GPIO_SPEED_FREQ_LOW
PE1.Mode=Asynchronous
PE1.Signal=USART1_RX
PE14.GPIO_Label=M1_OCP
PE14.GPIO_PuPd=GPIO_PULLUP
PE14.Mode=Activate-Break-Input-2
PE14.Signal=TIM1_BKIN2
PF4.GPIO_Label=PRECHARGE
PF4.PinState=GPIO_PIN_SET
PF4.Signal=GPIO_Output
PG0.GPIO_Label=GREEN_LED2
PG0.Signal=GPIO_Output
PG1.GPIO_Label=SPI1_CS
PG1.GPIO_PuPd=GPIO_PULLDOWN
PG1.GPIO_Speed=GPIO_SPEED_FREQ_VERY_HIGH
PG1.Signal=GPIO_Output
PG2.Mode=Full_Duplex_Master
PG2.Signal=SPI1_SCK
PG3.Mode=Full_Duplex_Master
PG3.Signal=SPI1_MISO
PG4.Mode=Full_Duplex_Master
PG4.Signal=SPI1_MOSI
ProjectManager.HeapSize=0x200
ProjectManager.StackSize=0x400
ProjectManager.TargetToolchain=EWARM V8
RCC.ADC12CLockSelection=RCC_ADC12CLKSOURCE_PLL
RCC.ADC12Freq_Value=42500000
RCC.ADC345CLockSelection=RCC_ADC345CLKSOURCE_PLL
RCC.ADC345Freq_Value=42500000
RCC.AHBFreq_Value=170000000
RCC.APB1Freq_Value=170000000
RCC.APB1TimFreq_Value=170000000
RCC.APB2Freq_Value=170000000
RCC.APB2TimFreq_Value=170000000
RCC.CortexFreq_Value=170000000
RCC.EXTERNAL_CLOCK_VALUE=12288000
RCC.FDCANCLockSelection=RCC_FDCANCLKSOURCE_PLL
RCC.HCLKFreq_Value=170000000
RCC.HSE_VALUE=8000000
RCC.HSI48_VALUE=48000000
RCC.HSI_VALUE=16000000
RCC.LSE_VALUE=32768
RCC.PLLM=RCC_PLLM_DIV4
RCC.PLLN=85
RCC.PLLP=RCC_PLLP_DIV8
RCC.PLLQ=RCC_PLLQ_DIV8
RCC.SYSCLKFreq_VALUE=170000000
RCC.SYSCLKSource=RCC_SYSCLKSOURCE_PLLCLK
RCC.USBFreq_Value=42500000
RCC.VCOOutputFreq_Value=340000000
SH.COMP_DAC11_group.0=DAC1_OUT1,DAC_OUT1
SH.COMP_DAC12_group.0=DAC1_OUT2,DAC_OUT2
SH.S_TIM1_CH1.0=TIM1_CH1,PWM Generation1 CH1 CH1N
SH.S_TIM1_CH2.0=TIM1_CH2,PWM Generation2 CH2 CH2N
SH.S_TIM1_CH3.0=TIM1_CH3,PWM Generation3 CH3 CH3N
SH.S_TIM2_CH1.0=TIM2_CH1,Encoder_Interface
SH.S_TIM2_CH2.0=TIM2_CH2,Encoder_Interface
SPI1.BaudRatePrescaler=SPI_BAUDRATEPRESCALER_64
SPI1.CLKPhase=SPI_PHASE_2EDGE
SPI1.CalculateBaudRate=2.65625 MBits/s
SPI1.DataSize=SPI_DATASIZE_8BIT
SPI1.Direction=SPI_DIRECTION_2LINES
SPI1.Mode=SPI_MODE_MASTER
SPI1.VirtualType=VM_MASTER
TIM1.AutoReloadPreload=TIM_AUTORELOAD_PRELOAD_DISABLE
TIM1.AutomaticOutput=TIM_AUTOMATICOUTPUT_DISABLE
TIM1.Break2Filter=0
TIM1.Break2Polarity=TIM_BREAK2POLARITY_HIGH
TIM1.Break2State=TIM_BREAK2_ENABLE
TIM1.BreakFilter=0
TIM1.BreakPolarity=TIM_BREAKPOLARITY_LOW
TIM1.BreakState=TIM_BREAK_DISABLE
TIM1.Channel=TIM_CHANNEL_4
TIM1.Channel-PWM\ Generation1\ CH1\ CH1N=TIM_CHANNEL_1
TIM1.Channel-PWM\ Generation2\ CH2\ CH2N=TIM_CHANNEL_2
TIM1.Channel-PWM\ Generation3\ CH3\ CH3N=TIM_CHANNEL_3
TIM1.Channel-PWM\ Generation4\ No\ Output=TIM_CHANNEL_4
TIM1.ClearInputSource=TIM_CLEARINPUTSOURCE_NONE
TIM1.ClockDivision=TIM_CLOCKDIVISION_DIV2
TIM1.CounterMode=TIM_COUNTERMODE_CENTERALIGNED1
TIM1.DeadTime=((DEAD_TIME_COUNTS) / 2)
TIM1.LockLevel=TIM_LOCKLEVEL_1
TIM1.OCFastMode_PWM=TIM_OCFAST_DISABLE
TIM1.OCIdleState_1=TIM_OCIDLESTATE_RESET
TIM1.OCIdleState_2=TIM_OCIDLESTATE_RESET
TIM1.OCIdleState_3=TIM_OCIDLESTATE_RESET
TIM1.OCIdleState_4=TIM_OCIDLESTATE_RESET
TIM1.OCIdleState_5=TIM_OCIDLESTATE_RESET
TIM1.OCIdleState_6=TIM_OCIDLESTATE_RESET
TIM1.OCMode_PWM-PWM\ Generation1\ CH1\ CH1N=TIM_OCMODE_PWM1
TIM1.OCMode_PWM-PWM\ Generation2\ CH2\ CH2N=TIM_OCMODE_PWM1
TIM1.OCMode_PWM-PWM\ Generation3\ CH3\ CH3N=TIM_OCMODE_PWM1
TIM1.OCMode_PWM-PWM\ Generation4\ No\ Output=TIM_OCMODE_PWM2
TIM1.OCNIdleState_1=TIM_OCNIDLESTATE_RESET
TIM1.OCNIdleState_2=TIM_OCNIDLESTATE_RESET
TIM1.OCNIdleState_3=TIM_OCNIDLESTATE_RESET
TIM1.OCNPolarity_1=TIM_OCNPOLARITY_HIGH
TIM1.OCNPolarity_2=TIM_OCNPOLARITY_HIGH
TIM1.OCNPolarity_3=TIM_OCNPOLARITY_HIGH
TIM1.OCPolarity_1=TIM_OCPOLARITY_HIGH
TIM1.OCPolarity_2=TIM_OCPOLARITY_HIGH
TIM1.OCPolarity_3=TIM_OCPOLARITY_HIGH
TIM1.OCPolarity_4=TIM_OCPOLARITY_HIGH
TIM1.OCPolarity_5=TIM_OCPOLARITY_HIGH
TIM1.OCPolarity_6=TIM_OCPOLARITY_HIGH
TIM1.OffStateIDLEMode=TIM_OSSI_ENABLE
TIM1.OffStateRunMode=TIM_OSSR_ENABLE
TIM1.Period=((PWM_PERIOD_CYCLES) / 2)
TIM1.PeriodNoDither=((PWM_PERIOD_CYCLES) / 2)
TIM1.Prescaler=((TIM_CLOCK_DIVIDER) - 1)
TIM1.Pulse-PWM\ Generation1\ CH1=((PWM_PERIOD_CYCLES) / 4)
TIM1.Pulse-PWM\ Generation2\ CH2=((PWM_PERIOD_CYCLES) / 4)
TIM1.Pulse-PWM\ Generation3\ CH3=((PWM_PERIOD_CYCLES) / 4)
TIM1.Pulse-PWM\ Generation4\ No\ Output=(((PWM_PERIOD_CYCLES) / 2) - (HTMIN))
TIM1.Pulse-PWM\ Generation5\ No\ Output=(((PWM_PERIOD_CYCLES) / 2) + 1)
TIM1.Pulse-PWM\ Generation6\ No\ Output=(((PWM_PERIOD_CYCLES) / 2) + 1)
TIM1.RepetitionCounter=(REP_COUNTER)
TIM1.SourceBRK2DigInput=TIM_BREAKINPUTSOURCE_ENABLE
TIM1.SourceBRK2DigInputPolarity=TIM_BREAKINPUTSOURCE_POLARITY_LOW
TIM1.TIM_MasterOutputTrigger=TIM_TRGO_OC4REF
TIM1.TIM_MasterOutputTrigger2=TIM_TRGO2_RESET
TIM1.TIM_MasterSlaveMode=TIM_MASTERSLAVEMODE_DISABLE
TIM1.TIM_SlaveMode=TIM_SLAVEMODE_TRIGGER
TIM16.AutoReloadPreload=TIM_AUTORELOAD_PRELOAD_ENABLE
TIM16.PeriodNoDither=9999
TIM16.Prescaler=1700
TIM17.AutoReloadPreload=TIM_AUTORELOAD_PRELOAD_ENABLE
TIM17.PeriodNoDither=9999
TIM17.Prescaler=1700
TIM2.EncoderMode=TIM_ENCODERMODE_TI12
TIM2.IC1Filter=M1_ENC_IC_FILTER
TIM2.IC1Polarity=TIM_ICPOLARITY_RISING
TIM2.IC2Filter=M1_ENC_IC_FILTER
TIM2.IC2Polarity=TIM_ICPOLARITY_RISING
TIM2.Period=M1_PULSE_NBR
TIM7.AutoReloadPreload=TIM_AUTORELOAD_PRELOAD_ENABLE
TIM7.PeriodNoDither=9999
TIM7.Prescaler=1699
USART1.BaudRate=115200
USART1.VirtualMode-Asynchronous=VM_ASYNC
USART1.WordLength=WORDLENGTH_8B
VP_CORDIC_VS_CORDIC.Mode=CORDIC_Activate
VP_MotorControl_MC_ENABLED.Mode=Enabled
VP_SYS_VS_DBSignals.Mode=DisableDeadBatterySignals
VP_TIM16_VS_ClockSourceINT.Mode=Enable_Timer
VP_TIM17_VS_ClockSourceINT.Mode=Enable_Timer
VP_TIM1_VS_ClockSourceITR.Mode=TriggerSource_ITR1
VP_TIM1_VS_ControllerModeTrigger.Mode=Trigger Mode
VP_TIM1_VS_no_output4.Mode=PWM Generation4 No Output
VP_TIM7_VS_ClockSourceINT.Mode=Enable_Timer
board=custom

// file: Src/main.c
/* USER CODE BEGIN Header */
/**
******************************************************************************
* @file           : main.c
* @brief          : Main program body
******************************************************************************
* @attention
*
* <h2><center>&copy; Copyright (c) 2026 STMicroelectronics.
* All rights reserved.</center></h2>
*
* This software component is licensed by ST under Ultimate Liberty license
* SLA0044, the "License"; You may not use this file except in compliance with
* the License. You may obtain a copy of the License at:
*                             www.st.com/SLA0044
*
******************************************************************************
*/
/* USER CODE END Header */

#include "main.h"
#include "motorcontrol.h"

/* USER CODE BEGIN Includes */
#include <stdlib.h>
#include <math.h>
#include "AS5x47P.h"
#include "EncoderFns.h"
#include "FDCAN.h"
#include "TemperatureLogic.h"
#include "StateMachine.h"
#include "Configuration.h"
#include "ControlFns.h"
#include "EncFaults.h"
#include "States.h"
#include "StartSequence.h"
#include "motor_config.h"

/* USER CODE END Includes */

/* USER CODE BEGIN PTD */

#define ON 1
#define OFF 0
#define MAX_TEMP_MOTOR 100
#define MAX_TEMP_MOSFET 100
#define MIN_TEMP_MOTOR 60
#define MIN_TEMP_MOSFET 60
#define CAPPING_TEMP_MOTOR 80
#define CAPPING_TEMP_MOSFET 80
/* USER CODE END PTD */

/* USER CODE BEGIN PD */

Temp t;
CAN_SS_Input canSSIp;
CAN_Continuous_Input canContIp;
continousControlTimer ccT;
systemState ss;
Config c;
laptopContinuousControl lcc;
EncFaults encFlts;
startSeq ssq;
brakeCtrl b;
EEConfig eecfg;
logController logC;
accelControl a;
loadObserver lo;
CustomPI pi;

extern FOCVars_t FOCVars[1];
extern int16_t hTargetSpeedUserDefined;
extern SpeednTorqCtrl_Handle_t *pSTC[NBR_OF_MOTORS];
/* USER CODE END PD */

ADC_HandleTypeDef hadc1;
ADC_HandleTypeDef hadc2;

CORDIC_HandleTypeDef hcordic;

DAC_HandleTypeDef hdac1;

FDCAN_HandleTypeDef hfdcan2;

SPI_HandleTypeDef hspi1;

TIM_HandleTypeDef htim1;
TIM_HandleTypeDef htim2;
TIM_HandleTypeDef htim7;
TIM_HandleTypeDef htim16;
TIM_HandleTypeDef htim17;

UART_HandleTypeDef huart1;

void SystemClock_Config(void);
static void MX_GPIO_Init(void);
static void MX_ADC1_Init(void);
static void MX_ADC2_Init(void);
static void MX_CORDIC_Init(void);
static void MX_DAC1_Init(void);
static void MX_FDCAN2_Init(void);
static void MX_SPI1_Init(void);
static void MX_TIM1_Init(void);
static void MX_TIM2_Init(void);
static void MX_USART1_UART_Init(void);
static void MX_TIM7_Init(void);
static void MX_TIM17_Init(void);
static void MX_TIM16_Init(void);
static void MX_NVIC_Init(void);
/* USER CODE BEGIN PFP */
RegConv_t Motor_ADC,MOSFET_ADC; // These ADC handlers are defined here to make it easy to see what ADCs we are reading.

/* USER CODE END PFP */

/* USER CODE BEGIN 0 */

uint8_t sendData, PCOn, activeDischarge;
FDCAN_RxHeaderTypeDef   RxHeader;
uint8_t RxData[8];

extern float k;
extern uint8_t CircleLimitationState;

uint8_t cc_turnOff = 0,triggerFault =0,nvicReset=0;
int16_t deltaRPM = 0, rpmError = 0;
FDCAN_RxHeaderTypeDef   RxHeader;
uint8_t RxData[8];
uint8_t CircleLimitationState;

uint8_t cc_stopMsg_oneTime=0;

uint8_t st_calib_on = 0,st_calib_off=0,st_increment=0,st_counter=0;
uint16_t step_current = 0,st_encVal_start=0,st_encVal=0,stEnc_absDeltaVal=0;
int16_t stEnc_deltaVal=0;

int16_t spiRaw = 0 ;
uint8_t triggerSPIAngleReading = 0;
float ABI_elAngle = 0,spi_elAngle=0,deltaAngles=0,encFault_deltaAngle=0,encFault_spiAngle=0;
uint8_t encFaultCounter = 0,testDirError = 0,resetCustomFaults=0,spi_FailCount = 0;
uint8_t ssqErrorState = 0,resetStartSeq=0;
State_t start_state;

uint8_t regenRampApplied = 0;
uint32_t startTickTime = 0;
extern MCI_Handle_t * pMCI[NBR_OF_MOTORS];

void manualStart(int8_t direction,uint16_t targetRPM,uint16_t brakeDistance);
uint8_t startManual = 0;

uint16_t minVoltage = 500;
uint8_t startVoltageMinning = 0;
/* USER CODE END 0 */

int main(void)
{

  /* MCU Configuration--------------------------------------------------------*/

  /* Reset of all peripherals, Initializes the Flash interface and the Systick. */
  HAL_Init();

  /* Configure the system clock */
  SystemClock_Config();

  /* Initialize all configured peripherals */
  MX_GPIO_Init();
  MX_ADC1_Init();
  MX_ADC2_Init();
  MX_CORDIC_Init();
  MX_DAC1_Init();
  MX_FDCAN2_Init();
  MX_SPI1_Init();
  MX_TIM1_Init();
  MX_TIM2_Init();
  MX_USART1_UART_Init();
  MX_MotorControl_Init();
  MX_TIM7_Init();
  MX_TIM17_Init();
  MX_TIM16_Init();

  /* Initialize interrupts */
  MX_NVIC_Init();
  /* USER CODE BEGIN 2 */

  HAL_GPIO_WritePin(PRECHARGE_GPIO_Port,PRECHARGE_Pin,GPIO_PIN_RESET);
  HAL_Delay(200);
  MC_AcknowledgeFaultMotor1();
  HAL_Delay(200);

  //set up interrupts for TIM2 encoder err detection
  __HAL_TIM_ENABLE_IT(&htim2, TIM_IT_DIR);
  __HAL_TIM_ENABLE_IT(&htim2, TIM_IT_IERR);
  __HAL_TIM_ENABLE_IT(&htim2, TIM_IT_TERR);

  HAL_TIM_Base_Start_IT(&htim7);
  HAL_TIM_Base_Start_IT(&htim17); // Timer 17 - Configured as interrupt -  100ms

  FDCAN_TxInit();
  FDCAN_RxFilterInit();
  HAL_Delay(1000); //wait for some time so that voltage at Encoder is also stabilized.

  t.motorHandler=InitializeADC(&Motor_ADC,ADC1,2,ADC_SAMPLETIME_6CYCLES_5);
  t.mosfetHandler=InitializeADC(&MOSFET_ADC,ADC1,3,ADC_SAMPLETIME_6CYCLES_5);

  ss.CustomFaults = NO_FAULTS;
  ss.cc_state = CC_IDLE;
  ss.customFaultErrorVal = 0;

  /********************* motor id verification from EEPROM ***************************/
  //Load Motor ID,sign for CW and position in POD from Eeprom
  //sign for CW = -1 means, motor shaft rotates counter clockwise when Iq is +ve
  //check if within Range, both readings are same.
  /*
  POD 5,motor10,signForCW=-1,LEFT_SIDE  /  motor6,signForCW= -1,RIGHT_SIDE
  POD 2,motor9, signForCW= 1,RIGHT_SIDE
  POD 4,motor5,signForCW= 1,LEFT_SIDE
  POD 3,motor3,signForCW= 1,RIGHT_SIDE
  */

  MotorConfig_Init();

  //Uncomment only once when programming a new inverter motor pair
  //MotorConfig_Write(10,-1,LEFT_SIDE);  // (motor ID, signforCW,positioninPod,

  if (MotorConfig_Read(&eecfg) == EE_OK){  //TODO : use uint8 or 16 bit read/write functions inside motorConfig
    if (CheckEEConfigValues(&eecfg) == EEPROM_VALUES_OK){
      c.motorID = eecfg.motorID;
      c.signForCWRotation = eecfg.signforCW;
      c.positionInPod = eecfg.positionInPod;
    }else{
      ss.CustomFaults = BAD_EEPROM_VALUES;
      ss.cc_state = CC_ERROR;
    }
  }else{
    ss.CustomFaults = EEPROM_READING_ERR;
    ss.cc_state = CC_ERROR;
  }

  /********************************************/

  if (ss.cc_state == CC_IDLE){ // if no errors use values read to setup inverter

      int16_t response = getMotorIndexFromMotorID(c.motorID);
      if (response != -1){
          c.zeroPos = response;
          c.EncoderZeroPosLoaded = updateEncoderZeroPosition(c.zeroPos);
          c.EncoderABIConfigLoaded = setupMotorEncoder_inABI_Mode();
          if (c.EncoderABIConfigLoaded == 0){ // this fault only comes during starting.
              ss.CustomFaults = ENCODER_INDEX_LOAD_FAIL; //If this fails, we dont let the machine to start
              ss.cc_state = CC_ERROR;
            }
      }else{
          ss.CustomFaults = BAD_MOTOR_INDEX;
          ss.cc_state = CC_ERROR;
      }
   }

  /*Now setup all state variables */
  if (ss.cc_state == CC_IDLE){
    InitializeEncFaults(&encFlts);
    initializeStartSeqParams(&ssq);

    CircleLimitationState = 0;

    ss.runType = NO_RUN;
    ss.cc_state = CC_IDLE;
    ss.cc_ramp = CC_RAMPOFF;

    ccT.PCM_timer_thresh = 6;
    cc_stopMsg_oneTime = 0;

    updateTMCMState(&ss); //voltage

   //Wait till State goes to IDLE. The turn the motor on and off , so that the ABI and SPI sensors synchronize.
    start_state = MC_GetSTMStateMotor1();
    if (start_state == IDLE){
      MC_ProgramSpeedRampMotor1(0, 300 );
      MC_StartMotor1();
      HAL_Delay(1000);
      TMCM_SpeedLoop_TurnOff();
    }else{
      //if state is not idle here, then some MCSDK fault. TODO: Read that fault and handle it
      ss.CustomFaults = START_IDLE_NOT_REACHED;
      ss.cc_state = CC_ERROR;
    }
  }

  //if any of the errors above have fired, do not allow the inverter to start. Error msgs to PCM will keep going from interrupt.
  if (ss.cc_state == CC_ERROR){
    while(1){
      //Wait for ever and keep sending error msg
      ss.neverStarting++;
      HAL_Delay(1000);
    }
  }

  //put same as drive param units cos we know theyre safe Kp = 14000/512, 5/1024. Kp is very small but large electrical noise.Ki is also very small
   pi.Kp = 14000;
   pi.KpPow2 = 9;
   pi.Ki = 5;
   pi.KiPow2 = 10;
   setCustomKpValues(&pi);

  /*
    PID_SetKP(&PIDSpeedHandle_M1, 24344);
    PID_SetKPDivisorPOW2(&PIDSpeedHandle_M1, 4);

    PID_SetKI(&PIDSpeedHandle_M1, 15552);
    PID_SetKIDivisorPOW2(&PIDSpeedHandle_M1, 9);

   //// Configure 12 Nm max Kp push at 50 RPM, Ti = 1s integral reset
    PID_SetKP(&PIDSpeedHandle_M1, 650);//was 1365
    PID_SetKPDivisorPOW2(&PIDSpeedHandle_M1, 0);

    PID_SetKI(&PIDSpeedHandle_M1, 350);
    PID_SetKIDivisorPOW2(&PIDSpeedHandle_M1, 8);
    */

    //to prevent spurious turns ons, for ten sec from here, any can msg received is ingested, but not acted upon
    startTickTime = HAL_GetTick();
    ss.startingDeadTimeCrossed = 0;

  // TODO: we also want to check temperature here and see if it is available, and also if its within limits when starting.
  // TODO : check voltage, if voltage not there, throw error and send codes.
  // TODO : Need to handle MCSDK errors properly, only custom errors are being checked
  // TODO : anywhere if MCSDK error, motor will stop automatically. Need to catch that and report in ss struct.
  /* USER CODE END 2 */

  /* Infinite loop */
  while (1)
  {

    /* USER CODE BEGIN 3 */

    ReadTemperatureADC(&t,MOTOR_TEMP); // has a delay inside so cant put in interrupt
    ReadTemperatureADC(&t,MOSFET_TEMP);
    ProcessTemperatureADCs(&t);
    updateTMCMState(&ss); //voltage

    if(resetCustomFaults){
      ss.cc_state =CC_IDLE;
      ss.CustomFaults = NO_FAULTS;
      resetCustomFaults = 0;
    }

    //----------------------------------------------
    //Happens for all types of run all the time.
    //Stop if SPI and ABI dont have the same reading.
    if (triggerSPIAngleReading){
      spiRaw = ENC_getRawReadingFromSPI();
      if (spiRaw==-1){
        AS5047_checkEncoderError(); // TODO: will clear the error on the chip -> later keep counts of which error and how many times.
        spi_FailCount ++;
        if (spi_FailCount >= 3){
          ss.CustomFaults = ENCODER_SPI_READ_FAIL;
          ss.cc_state = CC_ERROR;
          ss.distAtFault = ss.travelledDist;
          ss.faultTick = HAL_GetTick();
          ss.encoderFault  = 1;
        }
      }else{
        spi_FailCount = 0;
        ABI_elAngle = (float)(htim2.Instance->CNT%409)/409.6f *360.0f;
        spi_elAngle = (spiRaw %3276)/3276.0f*360.0f;
        deltaAngles = (ABI_elAngle - spi_elAngle);
        //handle rollover
        if (deltaAngles > 180.0f){deltaAngles -= 360.0f;}
        else if (deltaAngles < -180.0f){ deltaAngles += 360.0f;}
        //now check abs angle
        if (fabs(deltaAngles) > 10.0f){
          encFaultCounter++;
          if (encFaultCounter >=3){
            encFault_spiAngle = spi_elAngle;
            encFault_deltaAngle = deltaAngles;
            ss.CustomFaults = ENCODER_ABI_SPI_DELTA;
            ss.customFaultErrorVal = (int16_t)deltaAngles;
            ss.cc_state = CC_ERROR;
            ss.distAtFault = ss.travelledDist;
            ss.encoderFault  = 1;
            ss.faultTick = HAL_GetTick();
          }
        }else{
          encFaultCounter = 0;
        }
      }
      triggerSPIAngleReading =  0;
    }

    //-----------------------------------------------

    //manual continous running from an array
    if (lcc.start){
      laptopCC_on(&lcc);
      ss.podDirection = lcc.direction;
      ss.motorDirection = ss.podDirection;
      ss.cc_state = CC_RUNNING_CL;
      ss.cc_ramp = CC_RAMPUP;
      ss.runType=LCC;

      ss.travelledDist=0;

      ss.CL_DeltaRPMThreshold = Calculate_CLDeltaRPMThreshold(600);

      //reset logging.
      logC.startTickForDelayedStop = 0; // will reset timer in WaitmSecForStopping
      logC.logStopMsgSent = 0;
      ss.loggingOn = 1;

      DisableEncoderFltChking(&encFlts);
      ResetEncFaults(&encFlts);
      EnableEncoderFltChking(&encFlts);

      lcc.start = 0;
    }

    if (lcc.increment_signal){
      laptopCC_increment(&lcc,&ss);
      ss.indexID = lcc.idx;
      if (abs(lcc.target) < ss.targetRPM){
        ss.cc_ramp = CC_RAMPDOWN;
      }
      if ((ss.cc_ramp == CC_RAMPDOWN) && (abs(lcc.target) < 30)){
        lcc.stop = 1;
      }
      ss.targetRPM = lcc.target;
      lcc.increment_signal=0;
    }

    if(lcc.stop){
      a.ffActive = 0;
      lo.active = 0;
      TMCM_SpeedLoop_TurnOff();
      laptopCC_stop(&lcc);
      ss.targetRPM =  0;
      ss.indexID  = 0;
      ss.cc_state = CC_IDLE;
      ss.cc_ramp = CC_RAMPOFF;
      ss.runType=NO_RUN;
      lcc.stop = 0;
    }

    /*---end of lcc code -------*/

    //BRAKING FOR CC
    if (ss.cc_state == CC_RUNNING_CL){
      if (ss.travelledDist >= ss.brakeDistance){
        /* apply Regen one time only and when speed falls below minSpeed, applyBrake*/
        if (regenRampApplied == 0){
          lo.active = 0;
          a.ffActive = 0;
          applyRegen(ss.motorDirection);
          regenRampApplied = 1;
          ss.cc_ramp = CC_RAMPDOWN;  //whenever we regen we have to put state as cc_rampdown, and set cc_State as runingOL
          ss.cc_state = CC_RUNNING_OL;
        }
      }
    }

    //turn off during Regen. Whenever regen, state is being made RUNNING_OL. TODO: think if this is best way
    if (ss.cc_state == CC_RUNNING_OL){
      if (ss.currentAbsRpm < REGEN_TURNOFF_RPM){
        b.brakeCounter = 0;
        ss.engageBrake = 1;
      }
    }

    // hitting break once
    if (ss.engageBrake == 1){
        if (b.brakeCounter == 0){
           a.ffActive = 0;
           lo.active = 0;
           TMCM_SpeedLoop_TurnOff();
           FDCAN_SendControlledBrakeMsg();
           ss.brakeState++;
           b.brakeCounter++;
           ss.engageBrake = 0;
           ss.cc_ramp = CC_RAMPOFF;
           ss.cc_state = CC_ERROR; // has to be error to stop it looking at the continous can msgs
           FDCAN_SendPCMAckMsg(1);
        }
    }

    if (startManual){
      manualStart(1,500,4);
      startManual = 0;
      startVoltageMinning = 1;
    }

    if (startVoltageMinning){
      if (ss.DC_VOLTAGE < minVoltage){
        minVoltage = ss.DC_VOLTAGE;
      }

    }
      //Starting Seq
    if (ssq.PCM_startCommand == 1){
     //   ssqErrorState = ExecStartSeq(&ssq,&ss);
        ssqErrorState =  ExecStartSeqWithAccelFF(&ssq,&ss,&a,&lo);
        if (ssqErrorState != NO_ERROR){
          ssq.globalStartSeqTimer = 0;
          ss.CustomFaults = CC_START_SEQ_FAIL;
          ss.cc_state = CC_ERROR;
        }
    }

    if (resetStartSeq){
       resetStartSeqParams( &ssq);
       resetStartSeqErrorState( &ssq);
       resetStartSeq = 0;
    }

    //only after ssq transition is done, do we start looking at the current. otherwise the large current not moving check will fire.
    if ((ss.cc_state == CC_RUNNING_CL) && (ssq.speedRampStarted == 1)){
      //RPM condition 1
      if (abs(hTargetSpeedUserDefined) > 150){ //was 100, made 150 for vinayaks pod
        deltaRPM = abs(hTargetSpeedUserDefined) - ss.currentAbsRpm;
        if (deltaRPM < 0){deltaRPM = -deltaRPM;}
        if(deltaRPM > ss.CL_DeltaRPMThreshold){
            ss.cc_state = CC_ERROR;
            ss.CustomFaults = CC_CLOSED_LOOP_FAIL;
            ss.customFaultErrorVal = deltaRPM;
        }
      }

      //does away with logic in the initial call function where u can have a different threshold than these to nos. Remove that section
      if (ss.currentAbsRpm >= 1000){
        ss.CL_DeltaRPMThreshold = RPM_CLOSED_LOOP_THRESHOLD2;
      }else{
        ss.CL_DeltaRPMThreshold = RPM_CLOSED_LOOP_THRESHOLD_CC;
      }

       //if we re giving large current and not moving , stop.
       // DOESNT WORK WITH LCC
        uint16_t absIqRef = abs(FOCVars[0].Iqdref.q);
        if ((absIqRef > 4000) && (ss.currentAbsRpm < 5)){  //requires about 1300 to start.even with metal bed if we re giving so much and not moving,stop
          ss.cc_state = CC_ERROR;
          ss.CustomFaults = CC_OVC_STALL;
        }

       /* while motoring, if you detect motion in the opp direction , turn off. SHOULD WE keep this for REGEN also? In case regen doesnt stop youll go in reverse*/
       startEncoderChecking(&encFlts,ss.currentAbsRpm);
       stopEncoderChecking(&encFlts,abs(ss.targetRPM));
       if (encFlts.encoderCheckingOn){
         if (encFlts.EncoderErrFlag == 1){
            ss.cc_state = CC_ERROR;
           if (encFlts.directionErrFlag){
               ss.CustomFaults = ENCODER_DIR_ERROR;
               ss.distAtFault = ss.travelledDist;
               ss.encoderFault  = 1;
               ss.faultTick = HAL_GetTick();
           }
           else if (encFlts.indexErrFlag){
             ss.CustomFaults = ENCODER_INDEX_ERROR;
             ss.distAtFault = ss.travelledDist;
             ss.encoderFault  = 1;
             ss.faultTick = HAL_GetTick();
           }
           else if (encFlts.transitionErrFlag){
             ss.CustomFaults = ENCODER_TRANSITION_ERROR;
             ss.distAtFault = ss.travelledDist;
             ss.encoderFault  = 1;
             ss.faultTick = HAL_GetTick();
           }
           else{}
        }
       }
    } //closes RUNNING_CL

    if ((ss.cc_state == CC_ERROR) || (ss.cc_state ==CC_RUNNING_OL_ERROR)){ // turn off. running this continously prevents any other command from restarting the motor.Precharge command from PCM resets this.
        a.ffActive = 0;
        lo.active = 0;
        if (ss.CustomFaults == CC_CLOSED_LOOP_FAIL){
          if (regenRampApplied == 0){
            applyRegen(ss.motorDirection);
            regenRampApplied = 1;
            ss.cc_ramp = CC_RAMPDOWN;  //whenever we regen we have to put state as cc_rampdown, and set cc_State as runingOL
            ss.cc_state = CC_RUNNING_OL_ERROR;
          }

          if (ss.cc_state == CC_RUNNING_OL_ERROR){
            if (ss.currentAbsRpm < REGEN_TURNOFF_RPM){
              b.brakeCounter = 0;
              ss.engageBrake = 1;
            }
          }
        }
        else{
          TMCM_SpeedLoop_TurnOff();
          ccT.timerOnBool = 0;
          ss.cc_ramp = CC_RAMPOFF;
          ss.runType=NO_RUN;
          hTargetSpeedUserDefined=0;
          DisableEncoderFltChking(&encFlts);
          ssq.PCM_startCommand = 0;
        }

        // Here were checking if the encoder fault has led to the distance calculation of the encoder failing..
        if (ss.encoderFault  == 1){
          if (HAL_GetTick() - ss.faultTick  >= 1000){
            if (ss.travelledDist <= ss.distAtFault){
               TMCM_SpeedLoop_TurnOff();
               FDCAN_SendSlamBrakeMsg();
               ss.brakeState++;
               b.brakeCounter++;
            }else{
              ss.encoderFault = 0;
            }
          }
        }

    }

    /*---**FOR TESTING ON STRAIGHT SECTION ONLY AT HIGH SPEED ---**/
    /*TODO : during error ->  error goes to coasting then we never fire brake. here brake fires when dist is reached.
    We need to do something that changes action when error hits , maybe for some errors we can do regen, like CLOSED loop, etc where
    motor error is not there, otherwise we coast, and where speed is below some no, hit the brake.*/
    /* whatever the state, brake - will fire even when in error ->  */
    if (ss.travelledDist >= 20){ //hardcode
       a.ffActive = 0;
       lo.active = 0;
       TMCM_SpeedLoop_TurnOff();
       ss.cc_ramp = CC_RAMPOFF;
       ss.cc_state = CC_ERROR; // has to be error to stop it looking at the continous can msgs
       FDCAN_SendSlamBrakeMsg();
       ss.brakeState++;
       b.brakeCounter++;
       FDCAN_SendPCMAckMsg(1);
      }

    if (cc_turnOff){ // used everywhere to turn off correctly
      a.ffActive = 0;
      lo.active = 0;
      TMCM_SpeedLoop_TurnOff();
      ss.cc_ramp = CC_RAMPOFF;
      ss.cc_state = CC_FINISH;
      ss.runType=NO_RUN;
      hTargetSpeedUserDefined=0;
      DisableEncoderFltChking(&encFlts);
      FDCAN_SendPCMAckMsg(1);
      cc_turnOff = 0;
    }

    //if logging on, and runType == NO_RUN and absRPM < 50, then wait for 2-3 sec, send CAN msg, and then switch off logging.
    if (ss.loggingOn == 1 && ss.runType == NO_RUN){
      if (ss.currentAbsRpm < 50){
        if (logC.logStopMsgSent == 0){
          if(WaitmSecForStopping(&logC,2000) == 1){  //start a X sec timer, and then send the stop logging msg
            FDCan_SendStopLoggingMsg();
            logC.logStopMsgSent = 1;
            ss.loggingOn = 0;
          }
        }
      }else{
        logC.startTickForDelayedStop = 0; // will reset timer in WaitmSecForStopping
      }
    }

    if(nvicReset){
       HAL_NVIC_SystemReset();
    }

   //  HAL_GPIO_WritePin(FAULT_1_GPIO_Port,FAULT_1_Pin,GPIO_PIN_SET);
   //  HAL_GPIO_WritePin(FAULT_2_GPIO_Port,FAULT_2_Pin,GPIO_PIN_SET);

  }// closes while
  /* USER CODE END 3 */
}

void SystemClock_Config(void)
{
  RCC_OscInitTypeDef RCC_OscInitStruct = {0};
  RCC_ClkInitTypeDef RCC_ClkInitStruct = {0};
  RCC_PeriphCLKInitTypeDef PeriphClkInit = {0};

  /** Configure the main internal regulator output voltage
  */
  HAL_PWREx_ControlVoltageScaling(PWR_REGULATOR_VOLTAGE_SCALE1_BOOST);
  /** Initializes the CPU, AHB and APB busses clocks
  */
  RCC_OscInitStruct.OscillatorType = RCC_OSCILLATORTYPE_HSI;
  RCC_OscInitStruct.HSIState = RCC_HSI_ON;
  RCC_OscInitStruct.HSICalibrationValue = RCC_HSICALIBRATION_DEFAULT;
  RCC_OscInitStruct.PLL.PLLState = RCC_PLL_ON;
  RCC_OscInitStruct.PLL.PLLSource = RCC_PLLSOURCE_HSI;
  RCC_OscInitStruct.PLL.PLLM = RCC_PLLM_DIV4;
  RCC_OscInitStruct.PLL.PLLN = 85;
  RCC_OscInitStruct.PLL.PLLP = RCC_PLLP_DIV8;
  RCC_OscInitStruct.PLL.PLLQ = RCC_PLLQ_DIV8;
  RCC_OscInitStruct.PLL.PLLR = RCC_PLLR_DIV2;
  if (HAL_RCC_OscConfig(&RCC_OscInitStruct) != HAL_OK)
  {
    Error_Handler();
  }
  /** Initializes the CPU, AHB and APB busses clocks
  */
  RCC_ClkInitStruct.ClockType = RCC_CLOCKTYPE_HCLK|RCC_CLOCKTYPE_SYSCLK
                              |RCC_CLOCKTYPE_PCLK1|RCC_CLOCKTYPE_PCLK2;
  RCC_ClkInitStruct.SYSCLKSource = RCC_SYSCLKSOURCE_PLLCLK;
  RCC_ClkInitStruct.AHBCLKDivider = RCC_SYSCLK_DIV1;
  RCC_ClkInitStruct.APB1CLKDivider = RCC_HCLK_DIV1;
  RCC_ClkInitStruct.APB2CLKDivider = RCC_HCLK_DIV1;

  if (HAL_RCC_ClockConfig(&RCC_ClkInitStruct, FLASH_LATENCY_8) != HAL_OK)
  {
    Error_Handler();
  }
  /** Initializes the peripherals clocks
  */
  PeriphClkInit.PeriphClockSelection = RCC_PERIPHCLK_USART1|RCC_PERIPHCLK_ADC12
                              |RCC_PERIPHCLK_FDCAN;
  PeriphClkInit.Usart1ClockSelection = RCC_USART1CLKSOURCE_PCLK2;
  PeriphClkInit.FdcanClockSelection = RCC_FDCANCLKSOURCE_PLL;
  PeriphClkInit.Adc12ClockSelection = RCC_ADC12CLKSOURCE_PLL;
  if (HAL_RCCEx_PeriphCLKConfig(&PeriphClkInit) != HAL_OK)
  {
    Error_Handler();
  }
}

/**
  * @brief NVIC Configuration.
  * @retval None
  */
static void MX_NVIC_Init(void)
{
  /* TIM1_BRK_TIM15_IRQn interrupt configuration */
  HAL_NVIC_SetPriority(TIM1_BRK_TIM15_IRQn, 4, 1);
  HAL_NVIC_EnableIRQ(TIM1_BRK_TIM15_IRQn);
  /* TIM1_UP_TIM16_IRQn interrupt configuration */
  HAL_NVIC_SetPriority(TIM1_UP_TIM16_IRQn, 0, 0);
  HAL_NVIC_EnableIRQ(TIM1_UP_TIM16_IRQn);
  /* ADC1_2_IRQn interrupt configuration */
  HAL_NVIC_SetPriority(ADC1_2_IRQn, 2, 0);
  HAL_NVIC_EnableIRQ(ADC1_2_IRQn);
  /* TIM2_IRQn interrupt configuration */
  HAL_NVIC_SetPriority(TIM2_IRQn, 3, 0);
  HAL_NVIC_EnableIRQ(TIM2_IRQn);
  /* USART1_IRQn interrupt configuration */
  HAL_NVIC_SetPriority(USART1_IRQn, 3, 1);
  HAL_NVIC_EnableIRQ(USART1_IRQn);
  /* EXTI15_10_IRQn interrupt configuration */
  HAL_NVIC_SetPriority(EXTI15_10_IRQn, 3, 0);
  HAL_NVIC_EnableIRQ(EXTI15_10_IRQn);
}

static void MX_ADC1_Init(void)
{

  ADC_MultiModeTypeDef multimode = {0};
  ADC_InjectionConfTypeDef sConfigInjected = {0};
  ADC_ChannelConfTypeDef sConfig = {0};

  /** Common config
  */
  hadc1.Instance = ADC1;
  hadc1.Init.ClockPrescaler = ADC_CLOCK_ASYNC_DIV4;
  hadc1.Init.Resolution = ADC_RESOLUTION_12B;
  hadc1.Init.DataAlign = ADC_DATAALIGN_LEFT;
  hadc1.Init.GainCompensation = 0;
  hadc1.Init.ScanConvMode = ADC_SCAN_ENABLE;
  hadc1.Init.EOCSelection = ADC_EOC_SINGLE_CONV;
  hadc1.Init.LowPowerAutoWait = DISABLE;
  hadc1.Init.ContinuousConvMode = DISABLE;
  hadc1.Init.NbrOfConversion = 3;
  hadc1.Init.DiscontinuousConvMode = DISABLE;
  hadc1.Init.ExternalTrigConv = ADC_SOFTWARE_START;
  hadc1.Init.ExternalTrigConvEdge = ADC_EXTERNALTRIGCONVEDGE_NONE;
  hadc1.Init.DMAContinuousRequests = DISABLE;
  hadc1.Init.Overrun = ADC_OVR_DATA_PRESERVED;
  hadc1.Init.OversamplingMode = DISABLE;
  if (HAL_ADC_Init(&hadc1) != HAL_OK)
  {
    Error_Handler();
  }
  /** Configure the ADC multi-mode
  */
  multimode.Mode = ADC_MODE_INDEPENDENT;
  if (HAL_ADCEx_MultiModeConfigChannel(&hadc1, &multimode) != HAL_OK)
  {
    Error_Handler();
  }
  /** Configure Injected Channel
  */
  sConfigInjected.InjectedChannel = ADC_CHANNEL_7;
  sConfigInjected.InjectedRank = ADC_INJECTED_RANK_1;
  sConfigInjected.InjectedSamplingTime = ADC_SAMPLETIME_6CYCLES_5;
  sConfigInjected.InjectedSingleDiff = ADC_SINGLE_ENDED;
  sConfigInjected.InjectedOffsetNumber = ADC_OFFSET_NONE;
  sConfigInjected.InjectedOffset = 0;
  sConfigInjected.InjectedNbrOfConversion = 1;
  sConfigInjected.InjectedDiscontinuousConvMode = DISABLE;
  sConfigInjected.AutoInjectedConv = DISABLE;
  sConfigInjected.QueueInjectedContext = DISABLE;
  sConfigInjected.ExternalTrigInjecConv = ADC_EXTERNALTRIGINJEC_T1_TRGO;
  sConfigInjected.ExternalTrigInjecConvEdge = ADC_EXTERNALTRIGINJECCONV_EDGE_RISING;
  sConfigInjected.InjecOversamplingMode = DISABLE;
  if (HAL_ADCEx_InjectedConfigChannel(&hadc1, &sConfigInjected) != HAL_OK)
  {
    Error_Handler();
  }
  /** Configure Regular Channel
  */
  sConfig.Channel = ADC_CHANNEL_1;
  sConfig.Rank = ADC_REGULAR_RANK_1;
  sConfig.SamplingTime = ADC_SAMPLETIME_47CYCLES_5;
  sConfig.SingleDiff = ADC_SINGLE_ENDED;
  sConfig.OffsetNumber = ADC_OFFSET_NONE;
  sConfig.Offset = 0;
  if (HAL_ADC_ConfigChannel(&hadc1, &sConfig) != HAL_OK)
  {
    Error_Handler();
  }
  /** Configure Regular Channel
  */
  sConfig.Channel = ADC_CHANNEL_2;
  sConfig.Rank = ADC_REGULAR_RANK_2;
  sConfig.SamplingTime = ADC_SAMPLETIME_2CYCLES_5;
  if (HAL_ADC_ConfigChannel(&hadc1, &sConfig) != HAL_OK)
  {
    Error_Handler();
  }
  /** Configure Regular Channel
  */
  sConfig.Channel = ADC_CHANNEL_3;
  sConfig.Rank = ADC_REGULAR_RANK_3;
  if (HAL_ADC_ConfigChannel(&hadc1, &sConfig) != HAL_OK)
  {
    Error_Handler();
  }

}

static void MX_ADC2_Init(void)
{

  ADC_InjectionConfTypeDef sConfigInjected = {0};

  /** Common config
  */
  hadc2.Instance = ADC2;
  hadc2.Init.ClockPrescaler = ADC_CLOCK_ASYNC_DIV4;
  hadc2.Init.Resolution = ADC_RESOLUTION_12B;
  hadc2.Init.DataAlign = ADC_DATAALIGN_LEFT;
  hadc2.Init.GainCompensation = 0;
  hadc2.Init.ScanConvMode = ADC_SCAN_DISABLE;
  hadc2.Init.EOCSelection = ADC_EOC_SINGLE_CONV;
  hadc2.Init.LowPowerAutoWait = DISABLE;
  hadc2.Init.ContinuousConvMode = DISABLE;
  hadc2.Init.NbrOfConversion = 1;
  hadc2.Init.DiscontinuousConvMode = DISABLE;
  hadc2.Init.DMAContinuousRequests = DISABLE;
  hadc2.Init.Overrun = ADC_OVR_DATA_PRESERVED;
  hadc2.Init.OversamplingMode = DISABLE;
  if (HAL_ADC_Init(&hadc2) != HAL_OK)
  {
    Error_Handler();
  }
  /** Configure Injected Channel
  */
  sConfigInjected.InjectedChannel = ADC_CHANNEL_8;
  sConfigInjected.InjectedRank = ADC_INJECTED_RANK_1;
  sConfigInjected.InjectedSamplingTime = ADC_SAMPLETIME_6CYCLES_5;
  sConfigInjected.InjectedSingleDiff = ADC_SINGLE_ENDED;
  sConfigInjected.InjectedOffsetNumber = ADC_OFFSET_NONE;
  sConfigInjected.InjectedOffset = 0;
  sConfigInjected.InjectedNbrOfConversion = 1;
  sConfigInjected.InjectedDiscontinuousConvMode = DISABLE;
  sConfigInjected.AutoInjectedConv = DISABLE;
  sConfigInjected.QueueInjectedContext = DISABLE;
  sConfigInjected.ExternalTrigInjecConv = ADC_EXTERNALTRIGINJEC_T1_TRGO;
  sConfigInjected.ExternalTrigInjecConvEdge = ADC_EXTERNALTRIGINJECCONV_EDGE_RISING;
  sConfigInjected.InjecOversamplingMode = DISABLE;
  if (HAL_ADCEx_InjectedConfigChannel(&hadc2, &sConfigInjected) != HAL_OK)
  {
    Error_Handler();
  }

}

static void MX_CORDIC_Init(void)
{

  hcordic.Instance = CORDIC;
  if (HAL_CORDIC_Init(&hcordic) != HAL_OK)
  {
    Error_Handler();
  }

}

static void MX_DAC1_Init(void)
{

  DAC_ChannelConfTypeDef sConfig = {0};

  /** DAC Initialization
  */
  hdac1.Instance = DAC1;
  if (HAL_DAC_Init(&hdac1) != HAL_OK)
  {
    Error_Handler();
  }
  /** DAC channel OUT1 config
  */
  sConfig.DAC_HighFrequency = DAC_HIGH_FREQUENCY_INTERFACE_MODE_AUTOMATIC;
  sConfig.DAC_DMADoubleDataMode = DISABLE;
  sConfig.DAC_SignedFormat = DISABLE;
  sConfig.DAC_SampleAndHold = DAC_SAMPLEANDHOLD_DISABLE;
  sConfig.DAC_Trigger = DAC_TRIGGER_SOFTWARE;
  sConfig.DAC_Trigger2 = DAC_TRIGGER_NONE;
  sConfig.DAC_OutputBuffer = DAC_OUTPUTBUFFER_DISABLE;
  sConfig.DAC_ConnectOnChipPeripheral = DAC_CHIPCONNECT_DISABLE;
  sConfig.DAC_UserTrimming = DAC_TRIMMING_FACTORY;
  if (HAL_DAC_ConfigChannel(&hdac1, &sConfig, DAC_CHANNEL_1) != HAL_OK)
  {
    Error_Handler();
  }
  /** DAC channel OUT2 config
  */
  sConfig.DAC_Trigger = DAC_TRIGGER_NONE;
  sConfig.DAC_ConnectOnChipPeripheral = DAC_CHIPCONNECT_DISABLE;
  if (HAL_DAC_ConfigChannel(&hdac1, &sConfig, DAC_CHANNEL_2) != HAL_OK)
  {
    Error_Handler();
  }

}

static void MX_FDCAN2_Init(void)
{

  hfdcan2.Instance = FDCAN2;
  hfdcan2.Init.FrameFormat = FDCAN_FRAME_CLASSIC;
  hfdcan2.Init.Mode = FDCAN_MODE_NORMAL;
  hfdcan2.Init.AutoRetransmission = DISABLE;
  hfdcan2.Init.TransmitPause = ENABLE;
  hfdcan2.Init.ProtocolException = DISABLE;
  hfdcan2.Init.NominalPrescaler = 17;
  hfdcan2.Init.NominalSyncJumpWidth = 1;
  hfdcan2.Init.NominalTimeSeg1 = 2;
  hfdcan2.Init.NominalTimeSeg2 = 2;
  hfdcan2.Init.DataPrescaler = 1;
  hfdcan2.Init.DataSyncJumpWidth = 1;
  hfdcan2.Init.DataTimeSeg1 = 1;
  hfdcan2.Init.DataTimeSeg2 = 1;
  hfdcan2.Init.StdFiltersNbr = 0;
  hfdcan2.Init.ExtFiltersNbr = 0;
  hfdcan2.Init.TxFifoQueueMode = FDCAN_TX_FIFO_OPERATION;
  if (HAL_FDCAN_Init(&hfdcan2) != HAL_OK)
  {
    Error_Handler();
  }

}

static void MX_SPI1_Init(void)
{

  /* SPI1 parameter configuration*/
  hspi1.Instance = SPI1;
  hspi1.Init.Mode = SPI_MODE_MASTER;
  hspi1.Init.Direction = SPI_DIRECTION_2LINES;
  hspi1.Init.DataSize = SPI_DATASIZE_8BIT;
  hspi1.Init.CLKPolarity = SPI_POLARITY_LOW;
  hspi1.Init.CLKPhase = SPI_PHASE_2EDGE;
  hspi1.Init.NSS = SPI_NSS_SOFT;
  hspi1.Init.BaudRatePrescaler = SPI_BAUDRATEPRESCALER_64;
  hspi1.Init.FirstBit = SPI_FIRSTBIT_MSB;
  hspi1.Init.TIMode = SPI_TIMODE_DISABLE;
  hspi1.Init.CRCCalculation = SPI_CRCCALCULATION_DISABLE;
  hspi1.Init.CRCPolynomial = 7;
  hspi1.Init.CRCLength = SPI_CRC_LENGTH_DATASIZE;
  hspi1.Init.NSSPMode = SPI_NSS_PULSE_DISABLE;
  if (HAL_SPI_Init(&hspi1) != HAL_OK)
  {
    Error_Handler();
  }

}

static void MX_TIM1_Init(void)
{

  TIM_SlaveConfigTypeDef sSlaveConfig = {0};
  TIM_MasterConfigTypeDef sMasterConfig = {0};
  TIMEx_BreakInputConfigTypeDef sBreakInputConfig = {0};
  TIM_OC_InitTypeDef sConfigOC = {0};
  TIM_BreakDeadTimeConfigTypeDef sBreakDeadTimeConfig = {0};

  htim1.Instance = TIM1;
  htim1.Init.Prescaler = ((TIM_CLOCK_DIVIDER) - 1);
  htim1.Init.CounterMode = TIM_COUNTERMODE_CENTERALIGNED1;
  htim1.Init.Period = ((PWM_PERIOD_CYCLES) / 2);
  htim1.Init.ClockDivision = TIM_CLOCKDIVISION_DIV2;
  htim1.Init.RepetitionCounter = (REP_COUNTER);
  htim1.Init.AutoReloadPreload = TIM_AUTORELOAD_PRELOAD_DISABLE;
  if (HAL_TIM_Base_Init(&htim1) != HAL_OK)
  {
    Error_Handler();
  }
  if (HAL_TIM_PWM_Init(&htim1) != HAL_OK)
  {
    Error_Handler();
  }
  sSlaveConfig.SlaveMode = TIM_SLAVEMODE_TRIGGER;
  sSlaveConfig.InputTrigger = TIM_TS_ITR1;
  if (HAL_TIM_SlaveConfigSynchro(&htim1, &sSlaveConfig) != HAL_OK)
  {
    Error_Handler();
  }
  sMasterConfig.MasterOutputTrigger = TIM_TRGO_OC4REF;
  sMasterConfig.MasterOutputTrigger2 = TIM_TRGO2_RESET;
  sMasterConfig.MasterSlaveMode = TIM_MASTERSLAVEMODE_DISABLE;
  if (HAL_TIMEx_MasterConfigSynchronization(&htim1, &sMasterConfig) != HAL_OK)
  {
    Error_Handler();
  }
  sBreakInputConfig.Source = TIM_BREAKINPUTSOURCE_BKIN;
  sBreakInputConfig.Enable = TIM_BREAKINPUTSOURCE_ENABLE;
  sBreakInputConfig.Polarity = TIM_BREAKINPUTSOURCE_POLARITY_LOW;
  if (HAL_TIMEx_ConfigBreakInput(&htim1, TIM_BREAKINPUT_BRK2, &sBreakInputConfig) != HAL_OK)
  {
    Error_Handler();
  }
  sConfigOC.OCMode = TIM_OCMODE_PWM1;
  sConfigOC.Pulse = 0;
  sConfigOC.OCPolarity = TIM_OCPOLARITY_HIGH;
  sConfigOC.OCNPolarity = TIM_OCNPOLARITY_HIGH;
  sConfigOC.OCFastMode = TIM_OCFAST_DISABLE;
  sConfigOC.OCIdleState = TIM_OCIDLESTATE_RESET;
  sConfigOC.OCNIdleState = TIM_OCNIDLESTATE_RESET;
  if (HAL_TIM_PWM_ConfigChannel(&htim1, &sConfigOC, TIM_CHANNEL_1) != HAL_OK)
  {
    Error_Handler();
  }
  sConfigOC.Pulse = 0;
  if (HAL_TIM_PWM_ConfigChannel(&htim1, &sConfigOC, TIM_CHANNEL_2) != HAL_OK)
  {
    Error_Handler();
  }
  sConfigOC.Pulse = 0;
  if (HAL_TIM_PWM_ConfigChannel(&htim1, &sConfigOC, TIM_CHANNEL_3) != HAL_OK)
  {
    Error_Handler();
  }
  sConfigOC.OCMode = TIM_OCMODE_PWM2;
  sConfigOC.Pulse = 0;
  sConfigOC.OCNPolarity = TIM_OCNPOLARITY_HIGH;
  if (HAL_TIM_PWM_ConfigChannel(&htim1, &sConfigOC, TIM_CHANNEL_4) != HAL_OK)
  {
    Error_Handler();
  }
  sBreakDeadTimeConfig.OffStateRunMode = TIM_OSSR_ENABLE;
  sBreakDeadTimeConfig.OffStateIDLEMode = TIM_OSSI_ENABLE;
  sBreakDeadTimeConfig.LockLevel = TIM_LOCKLEVEL_1;
  sBreakDeadTimeConfig.DeadTime = ((DEAD_TIME_COUNTS) / 2);
  sBreakDeadTimeConfig.BreakState = TIM_BREAK_DISABLE;
  sBreakDeadTimeConfig.BreakPolarity = TIM_BREAKPOLARITY_LOW;
  sBreakDeadTimeConfig.BreakFilter = 0;
  sBreakDeadTimeConfig.BreakAFMode = TIM_BREAK_AFMODE_INPUT;
  sBreakDeadTimeConfig.Break2State = TIM_BREAK2_ENABLE;
  sBreakDeadTimeConfig.Break2Polarity = TIM_BREAK2POLARITY_HIGH;
  sBreakDeadTimeConfig.Break2Filter = 0;
  sBreakDeadTimeConfig.Break2AFMode = TIM_BREAK_AFMODE_INPUT;
  sBreakDeadTimeConfig.AutomaticOutput = TIM_AUTOMATICOUTPUT_DISABLE;
  if (HAL_TIMEx_ConfigBreakDeadTime(&htim1, &sBreakDeadTimeConfig) != HAL_OK)
  {
    Error_Handler();
  }
  HAL_TIM_MspPostInit(&htim1);

}

static void MX_TIM2_Init(void)
{

  TIM_Encoder_InitTypeDef sConfig = {0};
  TIM_MasterConfigTypeDef sMasterConfig = {0};

  htim2.Instance = TIM2;
  htim2.Init.Prescaler = 0;
  htim2.Init.CounterMode = TIM_COUNTERMODE_UP;
  htim2.Init.Period = M1_PULSE_NBR;
  htim2.Init.ClockDivision = TIM_CLOCKDIVISION_DIV1;
  htim2.Init.AutoReloadPreload = TIM_AUTORELOAD_PRELOAD_DISABLE;
  sConfig.EncoderMode = TIM_ENCODERMODE_TI12;
  sConfig.IC1Polarity = TIM_ICPOLARITY_RISING;
  sConfig.IC1Selection = TIM_ICSELECTION_DIRECTTI;
  sConfig.IC1Prescaler = TIM_ICPSC_DIV1;
  sConfig.IC1Filter = M1_ENC_IC_FILTER;
  sConfig.IC2Polarity = TIM_ICPOLARITY_RISING;
  sConfig.IC2Selection = TIM_ICSELECTION_DIRECTTI;
  sConfig.IC2Prescaler = TIM_ICPSC_DIV1;
  sConfig.IC2Filter = M1_ENC_IC_FILTER;
  if (HAL_TIM_Encoder_Init(&htim2, &sConfig) != HAL_OK)
  {
    Error_Handler();
  }
  sMasterConfig.MasterOutputTrigger = TIM_TRGO_RESET;
  sMasterConfig.MasterSlaveMode = TIM_MASTERSLAVEMODE_DISABLE;
  if (HAL_TIMEx_MasterConfigSynchronization(&htim2, &sMasterConfig) != HAL_OK)
  {
    Error_Handler();
  }

}

static void MX_TIM7_Init(void)
{

  TIM_MasterConfigTypeDef sMasterConfig = {0};

  htim7.Instance = TIM7;
  htim7.Init.Prescaler = 1699;
  htim7.Init.CounterMode = TIM_COUNTERMODE_UP;
  htim7.Init.Period = 9999;
  htim7.Init.AutoReloadPreload = TIM_AUTORELOAD_PRELOAD_ENABLE;
  if (HAL_TIM_Base_Init(&htim7) != HAL_OK)
  {
    Error_Handler();
  }
  sMasterConfig.MasterOutputTrigger = TIM_TRGO_RESET;
  sMasterConfig.MasterSlaveMode = TIM_MASTERSLAVEMODE_DISABLE;
  if (HAL_TIMEx_MasterConfigSynchronization(&htim7, &sMasterConfig) != HAL_OK)
  {
    Error_Handler();
  }

}

static void MX_TIM16_Init(void)
{

  htim16.Instance = TIM16;
  htim16.Init.Prescaler = 1700;
  htim16.Init.CounterMode = TIM_COUNTERMODE_UP;
  htim16.Init.Period = 9999;
  htim16.Init.ClockDivision = TIM_CLOCKDIVISION_DIV1;
  htim16.Init.RepetitionCounter = 0;
  htim16.Init.AutoReloadPreload = TIM_AUTORELOAD_PRELOAD_ENABLE;
  if (HAL_TIM_Base_Init(&htim16) != HAL_OK)
  {
    Error_Handler();
  }

}

static void MX_TIM17_Init(void)
{

  htim17.Instance = TIM17;
  htim17.Init.Prescaler = 1700;
  htim17.Init.CounterMode = TIM_COUNTERMODE_UP;
  htim17.Init.Period = 9999;
  htim17.Init.ClockDivision = TIM_CLOCKDIVISION_DIV1;
  htim17.Init.RepetitionCounter = 0;
  htim17.Init.AutoReloadPreload = TIM_AUTORELOAD_PRELOAD_ENABLE;
  if (HAL_TIM_Base_Init(&htim17) != HAL_OK)
  {
    Error_Handler();
  }

}

static void MX_USART1_UART_Init(void)
{

  huart1.Instance = USART1;
  huart1.Init.BaudRate = 115200;
  huart1.Init.WordLength = UART_WORDLENGTH_8B;
  huart1.Init.StopBits = UART_STOPBITS_1;
  huart1.Init.Parity = UART_PARITY_NONE;
  huart1.Init.Mode = UART_MODE_TX_RX;
  huart1.Init.HwFlowCtl = UART_HWCONTROL_NONE;
  huart1.Init.OverSampling = UART_OVERSAMPLING_16;
  huart1.Init.OneBitSampling = UART_ONE_BIT_SAMPLE_DISABLE;
  huart1.Init.ClockPrescaler = UART_PRESCALER_DIV1;
  huart1.AdvancedInit.AdvFeatureInit = UART_ADVFEATURE_NO_INIT;
  if (HAL_UART_Init(&huart1) != HAL_OK)
  {
    Error_Handler();
  }
  if (HAL_UARTEx_SetTxFifoThreshold(&huart1, UART_TXFIFO_THRESHOLD_1_8) != HAL_OK)
  {
    Error_Handler();
  }
  if (HAL_UARTEx_SetRxFifoThreshold(&huart1, UART_RXFIFO_THRESHOLD_1_8) != HAL_OK)
  {
    Error_Handler();
  }
  if (HAL_UARTEx_DisableFifoMode(&huart1) != HAL_OK)
  {
    Error_Handler();
  }

}

static void MX_GPIO_Init(void)
{
  GPIO_InitTypeDef GPIO_InitStruct = {0};

  /* GPIO Ports Clock Enable */
  __HAL_RCC_GPIOF_CLK_ENABLE();
  __HAL_RCC_GPIOC_CLK_ENABLE();
  __HAL_RCC_GPIOA_CLK_ENABLE();
  __HAL_RCC_GPIOE_CLK_ENABLE();
  __HAL_RCC_GPIOB_CLK_ENABLE();
  __HAL_RCC_GPIOD_CLK_ENABLE();
  __HAL_RCC_GPIOG_CLK_ENABLE();

  /*Configure GPIO pin Output Level */
  HAL_GPIO_WritePin(PRECHARGE_GPIO_Port, PRECHARGE_Pin, GPIO_PIN_SET);

  /*Configure GPIO pin Output Level */
  HAL_GPIO_WritePin(GPIOC, ACTIVE_DISCHARGE_Pin|FAULT_LED_Pin|GREEN_LED1_Pin, GPIO_PIN_RESET);

  /*Configure GPIO pin Output Level */
  HAL_GPIO_WritePin(CONTACTOR_COIL_GPIO_Port, CONTACTOR_COIL_Pin, GPIO_PIN_SET);

  /*Configure GPIO pin Output Level */
  HAL_GPIO_WritePin(GPIOD, FAULT_1_Pin|FAULT_2_Pin, GPIO_PIN_RESET);

  /*Configure GPIO pin Output Level */
  HAL_GPIO_WritePin(GPIOG, GREEN_LED2_Pin|SPI1_CS_Pin, GPIO_PIN_RESET);

  /*Configure GPIO pin : PRECHARGE_Pin */
  GPIO_InitStruct.Pin = PRECHARGE_Pin;
  GPIO_InitStruct.Mode = GPIO_MODE_OUTPUT_PP;
  GPIO_InitStruct.Pull = GPIO_NOPULL;
  GPIO_InitStruct.Speed = GPIO_SPEED_FREQ_LOW;
  HAL_GPIO_Init(PRECHARGE_GPIO_Port, &GPIO_InitStruct);

  /*Configure GPIO pins : ACTIVE_DISCHARGE_Pin FAULT_LED_Pin GREEN_LED1_Pin */
  GPIO_InitStruct.Pin = ACTIVE_DISCHARGE_Pin|FAULT_LED_Pin|GREEN_LED1_Pin;
  GPIO_InitStruct.Mode = GPIO_MODE_OUTPUT_PP;
  GPIO_InitStruct.Pull = GPIO_NOPULL;
  GPIO_InitStruct.Speed = GPIO_SPEED_FREQ_LOW;
  HAL_GPIO_Init(GPIOC, &GPIO_InitStruct);

  /*Configure GPIO pin : CONTACTOR_AUX_Pin */
  GPIO_InitStruct.Pin = CONTACTOR_AUX_Pin;
  GPIO_InitStruct.Mode = GPIO_MODE_INPUT;
  GPIO_InitStruct.Pull = GPIO_NOPULL;
  HAL_GPIO_Init(CONTACTOR_AUX_GPIO_Port, &GPIO_InitStruct);

  /*Configure GPIO pins : CONTACTOR_COIL_Pin FAULT_1_Pin FAULT_2_Pin */
  GPIO_InitStruct.Pin = CONTACTOR_COIL_Pin|FAULT_1_Pin|FAULT_2_Pin;
  GPIO_InitStruct.Mode = GPIO_MODE_OUTPUT_PP;
  GPIO_InitStruct.Pull = GPIO_NOPULL;
  GPIO_InitStruct.Speed = GPIO_SPEED_FREQ_LOW;
  HAL_GPIO_Init(GPIOD, &GPIO_InitStruct);

  /*Configure GPIO pin : GREEN_LED2_Pin */
  GPIO_InitStruct.Pin = GREEN_LED2_Pin;
  GPIO_InitStruct.Mode = GPIO_MODE_OUTPUT_PP;
  GPIO_InitStruct.Pull = GPIO_NOPULL;
  GPIO_InitStruct.Speed = GPIO_SPEED_FREQ_LOW;
  HAL_GPIO_Init(GREEN_LED2_GPIO_Port, &GPIO_InitStruct);

  /*Configure GPIO pin : SPI1_CS_Pin */
  GPIO_InitStruct.Pin = SPI1_CS_Pin;
  GPIO_InitStruct.Mode = GPIO_MODE_OUTPUT_PP;
  GPIO_InitStruct.Pull = GPIO_PULLDOWN;
  GPIO_InitStruct.Speed = GPIO_SPEED_FREQ_VERY_HIGH;
  HAL_GPIO_Init(SPI1_CS_GPIO_Port, &GPIO_InitStruct);

  /*Configure GPIO pin : Start_Stop_Pin */
  GPIO_InitStruct.Pin = Start_Stop_Pin;
  GPIO_InitStruct.Mode = GPIO_MODE_IT_FALLING;
  GPIO_InitStruct.Pull = GPIO_NOPULL;
  HAL_GPIO_Init(Start_Stop_GPIO_Port, &GPIO_InitStruct);

  /*Configure GPIO pin : INDEX_Pin */
  GPIO_InitStruct.Pin = INDEX_Pin;
  GPIO_InitStruct.Mode = GPIO_MODE_IT_RISING;
  GPIO_InitStruct.Pull = GPIO_NOPULL;
  HAL_GPIO_Init(INDEX_GPIO_Port, &GPIO_InitStruct);

  /* EXTI interrupt init*/
  HAL_NVIC_SetPriority(EXTI9_5_IRQn, 0, 0);
  HAL_NVIC_EnableIRQ(EXTI9_5_IRQn);

}

/* USER CODE BEGIN 4 */

// Modified function that replaces the weak function in MCSDK. Used to set the correct direction for the torque
// when the motor is wound opposite

void FOC_CalcCurrRef(uint8_t bMotor)
{
  if(FOCVars[bMotor].bDriveInput == INTERNAL)
  { int32_t totalIq_MotorSpace;
    int16_t hTeref = STC_CalcTorqueReference(pSTC[bMotor]);

    /* now convert compensation torque to what we want and apply it*/
    totalIq_MotorSpace = hTeref;
    a.rawIQ = hTeref;
    lo.rawIQ =hTeref;

    if (a.ffActive){
      totalIq_MotorSpace += (int32_t)a.accelFF_PK_s16;
    }
    a.IQwFF = totalIq_MotorSpace;
    lo.IQwaFF = totalIq_MotorSpace;

    if (lo.active){
      leunbergObserverExec(&lo);
      lo.compensationTorque_Nm_s16 = (int16_t)(lo.compensationTorque_Nm * NM_TO_S16_CONVERSION_FACTOR);
     // totalIq_MotorSpace += lo.compensationTorque_Nm_s16;
      //lo.IQw_aFF_wLO = totalIq_MotorSpace;
    }

    if (totalIq_MotorSpace > IQMAX) {
      totalIq_MotorSpace = IQMAX;
    } else if (totalIq_MotorSpace < -IQMAX) {
      totalIq_MotorSpace = -IQMAX;
    }

    lo.prevTorque_Nm = (float)totalIq_MotorSpace * S16_TO_NM_CONVERSION_FACTOR;
    FOCVars[bMotor].hTeref = totalIq_MotorSpace;

    // 2. Convert to Electrical Iq, flipping the sign if reverse wound
    if (c.signForCWRotation == -1) {
        FOCVars[bMotor].Iqdref.q = -(FOCVars[bMotor].hTeref);
    } else {
        FOCVars[bMotor].Iqdref.q = FOCVars[bMotor].hTeref;
    }

  }
}

void HAL_FDCAN_RxFifo0Callback(FDCAN_HandleTypeDef *hfdcan, uint32_t RxFifo0ITs)
{

  if((RxFifo0ITs & FDCAN_IT_RX_FIFO0_NEW_MESSAGE) != RESET)
  {
    /* Retreive Rx messages from RX FIFO0 */
    if (HAL_FDCAN_GetRxMessage(hfdcan, FDCAN_RX_FIFO0, &RxHeader, RxData) == HAL_OK)
    {
      FDCAN_parseForMotor();
    }
    if (HAL_FDCAN_ActivateNotification(hfdcan, FDCAN_IT_RX_FIFO0_NEW_MESSAGE, 0) != HAL_OK)
    {
      /* Notification Error */
      Error_Handler();
    }
  }
}
uint16_t _100ms_counter;
uint8_t stopCAN = 0;
uint8_t badTimer=0;

void HAL_TIM_PeriodElapsedCallback(TIM_HandleTypeDef *htim) {
  // This callback is automatically called by the HAL on the Intrupt Event when timer overflows
  if(htim->Instance == TIM17) /** 100ms timer **/
  {
    if(ccT.timerOnBool){ //continous control timer. if we dont get a reading for OVF thresh, turn off.
      ccT.PCM_timer ++;
      if (ccT.PCM_timer > ccT.PCM_timer_thresh){
        badTimer = ccT.PCM_timer;
        ss.CustomFaults = PCM_CANTIMER_OVF;
        ss.cc_state = CC_ERROR;
        ccT.timerOnBool = 0;
      }
    }

    _100ms_counter++;
    if(lcc.timerOn_bool){lcc.increment_signal=1;} //For manual continous control
    if (ssq.PCM_startCommand){ssq.globalStartSeqTimer+=100;}

    triggerSPIAngleReading = 1;
    ss.travelledDist += (ss.currentAbsRpm/1800.0f) * 0.6908f; //rpm /((60 * 10) * GR) * pi*D, D= 0.2m,newD = 0.22

    //KEEP SENDING DATA
    FDCAN_CC_TMCM_sendRunTimeData();
    FDCAN_CC_TMCM_sendStatusData();
    if (ss.cc_state == CC_ERROR){
      FDCAN_TMCM_StopFrame(ss.CustomFaults,ss.customFaultErrorVal);
    }
  }

}

void manualStart(int8_t direction,uint16_t targetRPM,uint16_t brakeDistance){

      if(direction==-1){ // REVERSE FROM APP
        if (c.positionInPod == LEFT_SIDE){ss.podDirection = -1;} // For signFor CW = 1,left side motor needs to rotate counter clockwise.
        if (c.positionInPod == RIGHT_SIDE){ss.podDirection = 1;} // For signFor CW = 1,right side motor needs to rotate clockwise.
      }
      else if(direction==1){ // FORWARD FROM APP
        if (c.positionInPod == LEFT_SIDE){ss.podDirection = 1;}  // opposite for above
        if (c.positionInPod == RIGHT_SIDE){ss.podDirection = -1;}
      }
      else{
        return;
      }

      ss.motorDirection = ss.podDirection;
      lo.localPolarity =  ss.motorDirection * c.signForCWRotation; //needed for load observer calcs

      ss.targetRPM = targetRPM; //canContIp.controlQty;
      ss.brakeDistance = brakeDistance;//canContIp.indexID;

      //safety checks
      if (ss.targetRPM >= 2500){
        return;
      }
      if (ss.brakeDistance >= 500){
        return;
      }

    //calculate acceleration vars here.
    calculateAccelerationVars(&ss, &a);
    //Zero LO vars
    ZeroLOVars(&lo); //turned on after the kick torque is applied

    ss.CL_DeltaRPMThreshold =  Calculate_CLDeltaRPMThreshold(ss.targetRPM);
    ss.loggingOn = 1;

    ss.CustomFaults = NO_FAULTS;
    ss.cc_state = CC_RUNNING_CL;
    ss.cc_ramp = CC_RAMPUP;
    ss.runType=CC;
    ss.travelledDist = 0;

    // at beginning of run make this zero
    regenRampApplied = 0;
    ss.distAtFault = 0;
    ss.faultTick = 0;
    ss.encoderFault = 0;

    //calculate acceleration vars for feedforward
    calculateAccelerationVars(&ss, &a);

    DisableEncoderFltChking(&encFlts);
    ResetEncFaults(&encFlts);
    EnableEncoderFltChking(&encFlts);

    FDCAN_SendPCMAckMsg(1);

    //start the StartSeq
    resetStartSeqParams( &ssq);
    resetStartSeqErrorState( &ssq);
    ssq.PCM_startCommand = 1;
}

uint16_t IndexPinCounter;
void HAL_GPIO_EXTI_Callback(uint16_t GPIO_Pin)
{
  if(GPIO_Pin == GPIO_PIN_5)
  {
    IndexPinCounter++;
  }
}
/* USER CODE END 4 */

void Error_Handler(void)
{
}

/************************ (C) COPYRIGHT STMicroelectronics *****END OF FILE****/
